VERSION "HNPBNNNYNNNNNNNNNNNNNNNNNNNNNNNNYNYYYYYYYY>4>%%%/4>'%**4YYY///"

NS_ :

BS_:

BU_: HFM IMU AP_HMI SalvatorX CAN2LIN_GW
VAL_TABLE_ Vt_APHMIInGarageParkingState 6 "GP_IN_DETECTED_BWD" 5 "GP_IN_DETECTED_FWD" 4 "GP_OUT_BWD" 3 "GP_OUT_FWD" 2 "GP_IN_SCAN_BWD" 1 "GP_IN_SCAN_FWD" 0 "GP_NOT_AVAIABLE" ;
VAL_TABLE_ DrivingTubeDirection 1 "LEFT" 0 "RIGHT" ;
VAL_TABLE_ DrivingTubeDisplay 3 "BOTH" 2 "REAR" 1 "FRONT" 0 "NONE" ;
VAL_TABLE_ TubeRadius 65535 "UNKNOWN" 65534 "INFINITE" ;
VAL_TABLE_ SV_SCREEN_REQUESTS 255 "NO_STREAM_CHANGE" 222 "DEBUG_RAW_CAMERAS_SFM" 221 "DEBUG_RAW_CAMERAS" 220 "DEBUG_COLOUR_BARS" 219 "DEBUG_CALIBRATION_OLMC_QUAD_VIEW" 218 "DEBUG_TESTSCREEN_4_CAMS" 217 "DEBUG_CALIBRATION_PGM_QUAD_VIEW" 216 "DEBUG_CALIBRATION_FLMC_QUAD_VIEW" 215 "DEBUG_RIGHT_CAMERA_CLEANING" 214 "DEBUG_RIGHT_CAMERA_EDGES" 213 "DEBUG_RIGHT_CAMERA_VECTORS" 212 "DEBUG_RIGHT_CAMERA_EXTERN" 211 "DEBUG_LEFT_CAMERA_CLEANING" 210 "DEBUG_LEFT_CAMERA_EDGES" 209 "DEBUG_LEFT_CAMERA_VECTORS" 208 "DEBUG_LEFT_CAMERA_EXTERN" 207 "DEBUG_REAR_CAMERA_CLEANING" 206 "DEBUG_REAR_CAMERA_EDGES" 205 "DEBUG_REAR_CAMERA_VECTORS" 204 "DEBUG_REAR_CAMERA_EXTERN" 203 "DEBUG_FRONT_CAMERA_CLEANING" 202 "DEBUG_FRONT_CAMERA_EDGES" 201 "DEBUG_FRONT_CAMERA_VECTORS" 200 "DEBUG_FRONT_CAMERA_EXTERN" 151 "SMARTPHONE_VIEW" 93 "IPA_TOP_VIEW" 92 "IPA_REAR_VIEW" 91 "IPA_FRONT_VIEW" 79 "ARA_PANORAMIC_IRREGULAR" 78 "ARA_PANORAMIC_NORMAL" 77 "ARA_REAR_IRREGULAR" 76 "ARA_REAR_NORMAL" 62 "KERB_VIEW_REAR" 61 "KERB_VIEW_FRONT" 49 "TRAILER_VIEW" 48 "PANORAMIC_REAR_VIEW" 47 "REAR_VIEW_SPLIT" 46 "REAR_VIEW_FULL" 34 "TOP_VIEW_PMD" 33 "TOP_VIEW_PSD" 32 "TOP_VIEW_SFM" 31 "TOP_VIEW" 18 "PANORAMIC_FRONT_VIEW" 17 "FRONT_VIEW_SPLIT" 16 "FRONT_VIEW_FULL" 15 "BOWL_VIEW_MODIFIED" 14 "BOWL_VIEW_14" 13 "BOWL_VIEW_13" 12 "BOWL_VIEW_12" 11 "BOWL_VIEW_11" 10 "BOWL_VIEW_10" 9 "BOWL_VIEW_9" 8 "BOWL_VIEW_8" 7 "BOWL_VIEW_7" 6 "BOWL_VIEW_6" 5 "BOWL_VIEW_5" 4 "BOWL_VIEW_4" 3 "BOWL_VIEW_3" 2 "BOWL_VIEW_2" 1 "BOWL_VIEW_1" 0 "BLANK_SCREEN" ;
VAL_TABLE_ Gesture_Code 31 "INVALID" 30 "NO_ACTION" 11 "FLICK" 10 "TRIPLE_CLICK" 9 "DOUBLE_CLICK" 8 "RAW" 7 "ROTATE" 6 "ZOOM" 5 "DRAG" 4 "RIGHT_CLICK" 3 "CLICK" 2 "RELEASE" 1 "LONG_PRESS" 0 "PRESS" ;
VAL_TABLE_ VSig_maxSpeed10Warning 2 "BLINKING" 1 "CONTINUOUS" 0 "OFF" ;
VAL_TABLE_ Vt_Lean_angle_signal_status 15 "Reserved" 14 "Reserved" 13 "Reserved" 12 "Reserved" 11 "Reserved" 10 "Reserved" 9 "Reserved" 8 "Reserved" 7 "Reserved" 6 "Reserved" 5 "Reserved" 4 "Reserved" 3 "Initialization running" 2 "Signal fault" 1 "Sensor not available" 0 "No error" ;
VAL_TABLE_ Vt_Sensor_status 15 "Not defined" 14 "Not defined" 13 "Not defined" 12 "Not defined" 11 "Not defined" 10 "Not defined" 9 "Not defined" 8 "Synchronization failure" 7 "Not defined" 6 "Not defined" 5 "Not defined" 4 "Synchronization underflow" 3 "Not defined" 2 "Overvoltage detected" 1 "Undervoltage detected" 0 "No error" ;
VAL_TABLE_ CECC_MODES 2 "CECC_ERROR" 1 "CECC_CONTROLLING" 0 "CECC_OFF" ;
VAL_TABLE_ CECC_LIMITING_FCNS 5 "CECC_CLOUD" 4 "CECC_FOLLOW" 3 "CECC_SPEED_LIMIT" 2 "CECC_CURVE" 1 "CECC_DRIVER" 0 "CECC_OFF" ;
VAL_TABLE_ VehicleId 12 "LI-DC507" 11 "F-TZ330" 10 "R-CO220" 9 "F-TZ5000" 8 "F-TZ990" 7 "PassatJapan" 6 "F-TZ880" 5 "F-TZ660" 4 "F-TZ440" 3 "GG-ZV542" 2 "F-TZ560" 1 "F-TZ2222" 0 "Fzg. unbekannt" ;
VAL_TABLE_ VTSig_Mode_Gaspedalkennlinie 2 "Vorgabe einer Gaspedalstellung" 1 "Modifiziert anhand Stützstellen" 0 "Originalkennlinie" ;
VAL_TABLE_ parkReq 3 "hold permanently" 2 "hold temporarily" 1 "release" 0 "stay" ;
VAL_TABLE_ gearReq 3 "forward" 2 "neutral" 1 "backward" 0 "stay" ;
VAL_TABLE_ GlblTm_Multiplex 2 "gpsTime" 1 "sysTimestamp" 0 "msgCount" ;
VAL_TABLE_ RCG_LED 1 "ein" 0 "aus" ;
VAL_TABLE_ SwitchACCOff 1 "yes" 0 "no" ;
VAL_TABLE_ SwitchACCOn 1 "yes" 0 "no" ;
VAL_TABLE_ InterventionTypeCenter 15 "LCA" 14 "no intervention" 13 "LCA" 12 "no intervention" 11 "LCA" 10 "no intervention" 9 "LCA" 8 "no intervention" 7 "LCA" 6 "no intervention" 5 "LCA" 4 "no intervention" 3 "LCA" 2 "no intervention" 1 "LCA" 0 "no intervention" ;
VAL_TABLE_ InterventionTypeLeftRight 15 "VWall & LDW" 14 "LDW" 13 "VWall" 12 "no intervention" 11 "VWall & LDW" 10 "LDW" 9 "VWall" 8 "no intervention" 7 "VWall & LDW" 6 "LDW" 5 "VWall" 4 "no intervention" 3 "VWall & LDW" 2 "LDW" 1 "VWall" 0 "no intervention" ;
VAL_TABLE_ VLongRequestType 1 "NORMAL_V_REQUEST" 0 "OFF" ;
VAL_TABLE_ ALongRequestType 2 "NORMAL_A_REQUEST" 1 "RAMP_DOWN_MODE" 0 "OFF" ;
VAL_TABLE_ AFFPJitterFrequency 3 "40Hz" 2 "30Hz" 1 "20Hz" 0 "10Hz" ;
VAL_TABLE_ AFFPJitterForm 3 "undef." 2 "Rectangle" 1 "Sawtooth" 0 "Sinus" ;
VAL_TABLE_ AFFPJitterAmplitude 7 "70% of AFFPForce" 6 "60% of AFFPForce" 5 "50% of AFFPForce" 4 "40% of AFFPForce" 3 "30% of AFFPForce" 2 "20% of AFFPForce" 1 "10% of AFFPForce" 0 "0% of AFFPForce" ;
VAL_TABLE_ AGB_IMU_True_False 1 "True" 0 "False" ;
VAL_TABLE_ AGB_IMU_InValid_Valid 1 "Invalid" 0 "Valid" ;
VAL_TABLE_ LateralMarginType 2 "Vehicle" 1 "CrashBarrier" 0 "Line" ;
VAL_TABLE_ VtAvidLed 1 "LED switched on" 0 "LED off" ;
VAL_TABLE_ VtAGB_ReqMaxEngTqStatus 1 "No AGB request active" 0 "AGB requests torque reduction" ;
VAL_TABLE_ LaLdwActiveState 7 "LDW Suppressed Right + Left" 6 "- *" 5 "LDW Suppressed Right" 4 "LDW Warning Right" 3 "LDW Suppressed Left" 2 "LDW Warning Left" 1 "- *" 0 "LDW Idle *" ;
VAL_TABLE_ LaLkaLcaActiveState 7 "LKA/LCA Suppressed Right + Left" 6 "LCA in Progress * (Intervention Right + Left so to say)" 5 "LKA Suppressed Right" 4 "LKA Intervention Right" 3 "LKA Suppressed Left" 2 "LKA Intervention Left" 1 "LKA Idle, LCA Suppressed *" 0 "LKA Idle *" ;
VAL_TABLE_ Vt_BOOL 0 "FALSE" 1 "TRUE" ;
VAL_TABLE_ Vt_APHMIGeneralScreen 0 "SYSTEM_NOT_ACTIVE" 1 "SCANNING_ACTIVE" 2 "PARKING_SPACE_SELECTION" 3 "REMOTE_APP_ACTIVE" 4 "MANEUVER_ACTIVE" 5 "MANEUVER_FINISHED" 6 "MANEUVER_INTERRUPTED" 7 "UNDO_MANEUVER_ACTIVE" 8 "START_REMOTE_APP" 9 "PARK_OUT_INIT" 10 "PARK_OUT_SIDE" 11 "MENU_REM" 12 "MANEUVER_ACTIVE_LONG_MAN" 13 "REM_SV" 14 "REM_MAN" 15 "REM_MAN_ACTIVE" ;
VAL_TABLE_ Vt_APHMIGeneralMessage 39 "PARKING_OUT_FINISHED_FALLBACK" 38 "PARKING_IN_FINISHED_FALLBACK" 37 "KEY_NOT_ALIVE" 36 "KEY_NOT_IN_RANGE" 35 "SLOW_DOWN" 34 "WAIT" 33 "LOW_ENERGY" 32 "UNDO_FINISHED" 31 "GARAGE_NOT_OPEN" 30 "PARKING_CANCELLED_STEER" 29 "PARKING_CANCELLED_THROTTLE" 28 "NO_REMOTE_DEVICE_CONNECTED" 27 "NO_REMOTE_DEVICE_PAIRED" 26 "SELECT_PARKING_VARIANT" 25 "SHIFT_TO_N" 24 "SHIFT_TO_P" 0 "NO_MESSAGE" 1 "VERY_CLOSE_TO_OBJECTS" 2 "START_PARKING_IN" 3 "PARKING_IN_FINISHED" 4 "PARKING_CANCELLED" 5 "PARKING_FAILED" 6 "SHIFT_TO_R" 7 "SHIFT_TO_D" 8 "SHIFT_TO_1" 9 "RELEASE_BRAKE" 10 "START_PARKING_OUT" 11 "PARKING_OUT_FINISHED" 12 "START_REM_MAN" 13 "REM_MAN_OBSTACLE_STOP" 14 "REDUCE_DISTANCE_TO_VEHICLE" 15 "CLOSE_DOOR_OR_START_REMOTE" 16 "RELEASE_HANDBRAKE" 17 "LEAVE_VEHICLE" 18 "NO_DRIVER_DETECTED_ON_SEAT" 19 "INTERNAL_SYSTEM_ERROR" 20 "PARKING_OUT_HANDOVER" 21 "STEERING_ACTIVE" 22 "STOP" 23 "MAX_WAITING_TIME_EXCEEDED" ;
VAL_TABLE_ Vt_APHMIGeneralDrivingDir 0 "NO_DIRECTION" 1 "FORWARDS" 2 "BACKWARDS" ;
VAL_TABLE_ Vt_APHMIGeneralAVGType 0 "NO_AVG_TYPE" 1 "PARK_IN_PARALLEL_LEFT" 2 "PARK_IN_PARALLEL_RIGHT" 3 "PARK_IN_PERPENDICULAR_LEFT_FWD" 4 "PARK_IN_PERPENDICULAR_LEFT_BWD" 5 "PARK_IN_PERPENDICULAR_RIGHT_FWD" 6 "PARK_IN_PERPENDICULAR_RIGHT_BWD" 7 "PARK_OUT_PARALLEL_LEFT" 8 "PARK_OUT_PARALLEL_RIGHT" 9 "PARK_OUT_PERPENDICULAR_LEFT_FWD" 10 "PARK_OUT_PERPENDICULAR_LEFT_BWD" 11 "PARK_OUT_PERPENDICULAR_RIGHT_FWD" 12 "PARK_OUT_PERPENDICULAR_RIGHT_BWD" 13 "REM_MAN_FWD" 14 "REM_MAN_BWD" ;
VAL_TABLE_ Vt_APHMICurrentGear 0 "N" 1 "1" 2 "2" 3 "3" 4 "4" 5 "5" 6 "6" 7 "7" 8 "8" 9 "9" 10 "INTERMEDIATE_POS" 11 "R" 12 "P" 13 "S" 14 "GEAR_NOT_DEFINED" 15 "ERROR" ;
VAL_TABLE_ Vt_APHMIParkStatProcCtrlState 0 "PPC_INACTIVE" 1 "PPC_BEHAVIOR_INACTIVE" 2 "PPC_SCANNING_INACTIVE" 3 "PPC_SCANNING_IN" 4 "PPC_SCANNING_OUT" 5 "PPC_SCANNING_RM" 6 "PPC_PARKING_INACTIVE" 7 "PPC_PREPARE_PARKING" 8 "PPC_PERFORM_PARKING" 9 "PPC_PARKING_PAUSE" 10 "PPC_PARKING_FAILED" 11 "PPC_OFFER_HANDOVER" 12 "PPC_SUCCESS" 13 "PPC_PARKING_CANCELED" 14 "PPC_IRREVERSIBLE_ERROR" 15 "PPC_REVERSIBLE_ERROR" 23 "PPC_DEMO_OFF" ;
VAL_TABLE_ Vt_APHMIParkSlotPossOrient 0 "CERTAIN" 1 "UNCERTAIN" ;
VAL_TABLE_ Vt_APHMIParkSlotSelOrient 0 "PARALLEL" 1 "PERPENDICULAR" ;
VAL_TABLE_ Vt_APHMIParkSlotPossDir 0 "ONE_DIRECTION" 1 "BOTH_DIRECTIONS" ;
VAL_TABLE_ Vt_APHMIParkSlotSelDir 0 "FORWARDS" 1 "BACKWARDS" ;
VAL_TABLE_ Vt_APHMIParkDistViewLow 0 "L_NOT_OCCUPIED" 1 "L_OUTERMOST_BAR_OCCUPIED" 2 "L_BAR_2_OCCUPIED" 3 "L_INNERMOST_BAR_OCCUPIED" ;
VAL_TABLE_ Vt_APHMIParkDistViewHigh 0 "H_NOT_OCCUPIED" 1 "H_OUTERMOST_BAR_OCCUPIED" 2 "H_BAR_2_OCCUPIED" 3 "H_BAR_3_OCCUPIED" 4 "H_BAR_4_OCCUPIED" 5 "H_BAR_5_OCCUPIED" 6 "H_BAR_6_OCCUPIED" 7 "H_INNERMOST_BAR_OCCUPIED" ;
VAL_TABLE_ Vt_APHMIScreenDisplayed 0 "SYSTEM_NOT_ACTIVE" 1 "SCANNING_ACTIVE" 2 "PARKING_SPACE_SELECTION" 3 "REMOTE_APP_ACTIVE" 4 "MANEUVER_ACTIVE" 5 "MANEUVER_FINISHED" 6 "MANEUVER_INTERRUPTED" 7 "UNDO_MANEUVER_ACTIVE" 8 "START_REMOTE_APP" 9 "PARK_OUT_INIT" 10 "PARK_OUT_SIDE" 11 "MENU_REM" 12 "MANEUVER_ACTIVE_LONG_MAN" 13 "REM_SV" 14 "REM_MAN" 15 "REM_MAN_ACTIVE" ;
VAL_TABLE_ Vt_APHMIPushedButton 0 "NO_USER_ACTION" 1 "TAP_ON_PARKING_SPACE_LEFT_1" 2 "TAP_ON_PARKING_SPACE_LEFT_2" 3 "TAP_ON_PARKING_SPACE_LEFT_3" 4 "TAP_ON_PARKING_SPACE_LEFT_4" 5 "TAP_ON_PARKING_SPACE_RIGHT_1" 6 "TAP_ON_PARKING_SPACE_RIGHT_2" 7 "TAP_ON_PARKING_SPACE_RIGHT_3" 8 "TAP_ON_PARKING_SPACE_RIGHT_4" 9 "TAP_ON_PARKING_SPACE_FRONT_1" 10 "TAP_ON_PARKING_SPACE_FRONT_2" 11 "TAP_ON_PARKING_SPACE_FRONT_3" 12 "TAP_ON_PARKING_SPACE_FRONT_4" 13 "TAP_ON_PARKING_SPACE_REAR_1" 14 "TAP_ON_PARKING_SPACE_REAR_2" 15 "TAP_ON_PARKING_SPACE_REAR_3" 16 "TAP_ON_PARKING_SPACE_REAR_4" 17 "TAP_ON_START_SELECTION" 18 "TAP_ON_START_PARKING" 19 "TAP_ON_INTERRUPT" 20 "TAP_ON_CONTINUE" 21 "TAP_ON_UNDO" 22 "TAP_ON_CANCEL" 23 "TAP_ON_REDO" 24 "TAP_ON_START_REMOTE_PARKING" 25 "TAP_ON_SWITCH_DIRECTION" 26 "TAP_ON_SWITCH_ORIENTATION" 27 "TAP_ON_PREVIOUS_SCREEN" 28 "TOGGLE_AP_ACTIVE" ;
VAL_TABLE_ Vt_ParkSituation 0 "NO_SITUATION" 1 "PERPENDICULAR" 2 "PARALLEL" 3 "ANGLED" 4 "STREET" 5 "UNCERTAIN" 6 "PARALLEL_OUT" 7 "NOT_AVAILABLE" 15 "SNA" ;
VAL_TABLE_ Vt_PushedButton 0 "NO_USER_ACTION" 1 "TAP_ON_PARKING_SPACE_LEFT_1" 2 "TAP_ON_PARKING_SPACE_LEFT_2" 3 "TAP_ON_PARKING_SPACE_LEFT_3" 4 "TAP_ON_PARKING_SPACE_LEFT_4" 5 "TAP_ON_PARKING_SPACE_RIGHT_1" 6 "TAP_ON_PARKING_SPACE_RIGHT_2" 7 "TAP_ON_PARKING_SPACE_RIGHT_3" 8 "TAP_ON_PARKING_SPACE_RIGHT_4" 9 "TAP_ON_PARKING_SPACE_FRONT_1" 10 "TAP_ON_PARKING_SPACE_FRONT_2" 11 "TAP_ON_PARKING_SPACE_FRONT_3" 12 "TAP_ON_PARKING_SPACE_FRONT_4" 13 "TAP_ON_PARKING_SPACE_REAR_1" 14 "TAP_ON_PARKING_SPACE_REAR_2" 15 "TAP_ON_PARKING_SPACE_REAR_3" 16 "TAP_ON_PARKING_SPACE_REAR_4" 17 "TAP_ON_START_SELECTION" 18 "TAP_ON_START_PARKING" 19 "TAP_ON_INTERRUPT" 20 "TAP_ON_CONTINUE" 21 "TAP_ON_UNDO" 22 "TAP_ON_CANCEL" 23 "TAP_ON_REDO" 24 "TAP_ON_START_REMOTE_PARKING" 25 "TAP_ON_SWITCH_DIRECTION" 26 "TAP_ON_SWITCH_ORIENTATION" 27 "TAP_ON_PREVIOUS_SCREEN" 28 "TOGGLE_AP_ACTIVE" ;

BO_ 3221225472 VECTOR__INDEPENDENT_SIG_MSG: 0 Vector__XXX
 SG_ APHMIGeneralReserved : 0|1@1+ (1,0) [0|0] "" Vector__XXX

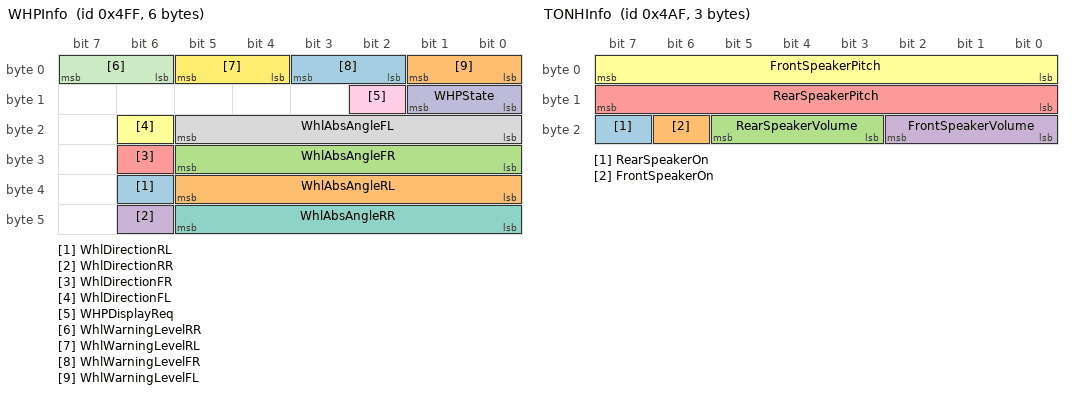
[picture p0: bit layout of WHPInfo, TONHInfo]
BO_ 1279 WHPInfo: 6 SalvatorX
 SG_ WhlDirectionRL : 38|1@1+ (1,0) [0|0] ""  AP_HMI
 SG_ WhlAbsAngleRL : 32|6@1+ (1,0) [0|0] "deg"  AP_HMI
 SG_ WhlAbsAngleFR : 24|6@1+ (1,0) [0|0] "deg"  AP_HMI
 SG_ WhlDirectionRR : 46|1@1+ (1,0) [0|0] ""  AP_HMI
 SG_ WhlDirectionFR : 30|1@1+ (1,0) [0|0] ""  AP_HMI
 SG_ WhlDirectionFL : 22|1@1+ (1,0) [0|0] ""  AP_HMI
 SG_ WhlAbsAngleRR : 40|6@1+ (1,0) [0|0] "deg"  AP_HMI
 SG_ WhlAbsAngleFL : 16|6@1+ (1,0) [0|0] "deg"  AP_HMI
 SG_ WHPDisplayReq : 10|1@1+ (1,0) [0|1] ""  AP_HMI
 SG_ WHPState : 8|2@1+ (1,0) [0|3] ""  AP_HMI
 SG_ WhlWarningLevelRR : 6|2@1+ (1,0) [0|3] ""  AP_HMI
 SG_ WhlWarningLevelRL : 4|2@1+ (1,0) [0|3] ""  AP_HMI
 SG_ WhlWarningLevelFR : 2|2@1+ (1,0) [0|3] ""  AP_HMI
 SG_ WhlWarningLevelFL : 0|2@1+ (1,0) [0|3] ""  AP_HMI

BO_ 1199 TONHInfo: 3 SalvatorX
 SG_ RearSpeakerOn : 23|1@1+ (1,0) [0|1] ""  AP_HMI
 SG_ FrontSpeakerOn : 22|1@1+ (1,0) [0|1] ""  AP_HMI
 SG_ RearSpeakerVolume : 19|3@1+ (1,0) [0|7] ""  AP_HMI
 SG_ FrontSpeakerVolume : 16|3@1+ (1,0) [0|7] ""  AP_HMI
 SG_ RearSpeakerPitch : 8|8@1+ (1,0) [0|255] ""  AP_HMI
 SG_ FrontSpeakerPitch : 0|8@1+ (1,0) [0|255] ""  AP_HMI

BO_ 1198 APHMIOut4: 8 AP_HMI
 SG_ APHMIOutRemScreenResY : 14|14@1+ (1,0) [0|16384] "px"  SalvatorX
 SG_ APHMIOutRemScreenResX : 0|14@1+ (1,0) [0|16384] "px"  SalvatorX

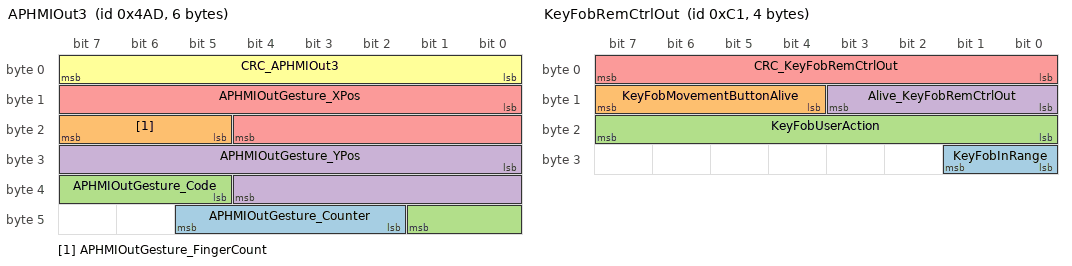
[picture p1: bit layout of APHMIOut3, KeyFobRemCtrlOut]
BO_ 1197 APHMIOut3: 6 AP_HMI
 SG_ APHMIOutGesture_Counter : 42|4@1+ (1,0) [0|15] ""  SalvatorX
 SG_ APHMIOutGesture_FingerCount : 21|3@1+ (1,0) [0|0] ""  SalvatorX
 SG_ APHMIOutGesture_Code : 37|5@1+ (1,0) [0|0] ""  SalvatorX
 SG_ APHMIOutGesture_YPos : 24|13@1+ (1,0) [0|0] ""  SalvatorX
 SG_ APHMIOutGesture_XPos : 8|13@1+ (1,0) [0|0] ""  SalvatorX
 SG_ CRC_APHMIOut3 : 0|8@1+ (1,0) [0|0] ""  SalvatorX

BO_ 193 KeyFobRemCtrlOut: 4 HFM
 SG_ KeyFobInRange : 24|2@1+ (1,0) [0|3] ""  SalvatorX
 SG_ KeyFobMovementButtonAlive : 12|4@1+ (1,0) [0|15] ""  SalvatorX
 SG_ KeyFobUserAction : 16|8@1+ (1,0) [0|255] ""  SalvatorX
 SG_ Alive_KeyFobRemCtrlOut : 8|4@1+ (1,0) [0|15] ""  SalvatorX
 SG_ CRC_KeyFobRemCtrlOut : 0|8@1+ (1,0) [0|255] ""  SalvatorX

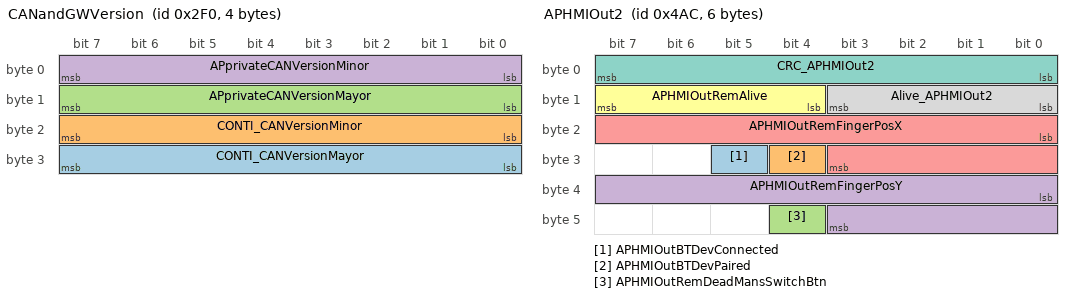
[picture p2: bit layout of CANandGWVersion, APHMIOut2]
BO_ 752 CANandGWVersion: 4 SalvatorX
 SG_ CONTI_CANVersionMayor : 24|8@1+ (1,0) [0|255] ""  AP_HMI
 SG_ CONTI_CANVersionMinor : 16|8@1+ (1,0) [0|255] ""  AP_HMI
 SG_ APprivateCANVersionMayor : 8|8@1+ (1,0) [0|255] ""  AP_HMI
 SG_ APprivateCANVersionMinor : 0|8@1+ (1,0) [0|255] ""  AP_HMI

BO_ 1196 APHMIOut2: 6 AP_HMI
 SG_ APHMIOutBTDevConnected : 29|1@1+ (1,0) [0|1] ""  SalvatorX
 SG_ APHMIOutBTDevPaired : 28|1@1+ (1,0) [0|1] ""  SalvatorX
 SG_ APHMIOutRemDeadMansSwitchBtn : 44|1@1+ (1,0) [0|1] ""  SalvatorX
 SG_ APHMIOutRemFingerPosY : 32|12@1+ (1,0) [0|4095] "px"  SalvatorX
 SG_ APHMIOutRemFingerPosX : 16|12@1+ (1,0) [0|4095] "px"  SalvatorX
 SG_ APHMIOutRemAlive : 12|4@1+ (1,0) [0|15] ""  SalvatorX
 SG_ CRC_APHMIOut2 : 0|8@1+ (1,0) [0|255] ""  SalvatorX
 SG_ Alive_APHMIOut2 : 8|4@1+ (1,0) [0|15] ""  SalvatorX

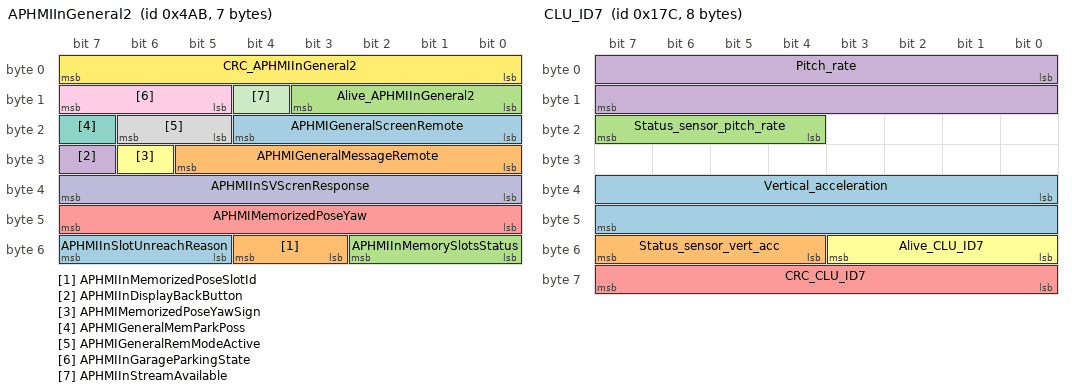
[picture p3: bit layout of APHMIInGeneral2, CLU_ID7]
BO_ 1195 APHMIInGeneral2: 7 SalvatorX
 SG_ APHMIInSlotUnreachReason : 53|3@1+ (1,0) [0|7] ""  AP_HMI
 SG_ APHMIInMemorizedPoseSlotId : 51|2@1+ (1,0) [0|3] ""  AP_HMI
 SG_ APHMIInMemorySlotsStatus : 48|3@1+ (1,0) [0|7] ""  AP_HMI
 SG_ APHMIInDisplayBackButton : 31|1@1+ (1,0) [0|1] ""  AP_HMI
 SG_ APHMIMemorizedPoseYaw : 40|8@1+ (1,0) [0|180] "deg"  AP_HMI
 SG_ APHMIMemorizedPoseYawSign : 30|1@1+ (1,0) [0|1] ""  AP_HMI
 SG_ APHMIGeneralMemParkPoss : 23|1@1+ (1,0) [0|1] ""  AP_HMI
 SG_ APHMIGeneralRemModeActive : 21|2@1+ (1,0) [0|3] ""  AP_HMI
 SG_ APHMIInGarageParkingState : 13|3@1+ (1,0) [0|0] ""  AP_HMI
 SG_ APHMIInSVScrenResponse : 32|8@1+ (1,0) [0|0] ""  AP_HMI
 SG_ APHMIInStreamAvailable : 12|1@1+ (1,0) [0|0] ""  AP_HMI
 SG_ CRC_APHMIInGeneral2 : 0|8@1+ (1,0) [0|255] ""  AP_HMI
 SG_ APHMIGeneralScreenRemote : 16|5@1+ (1,0) [0|0] ""  AP_HMI
 SG_ APHMIGeneralMessageRemote : 24|6@1+ (1,0) [0|0] ""  AP_HMI
 SG_ Alive_APHMIInGeneral2 : 8|4@1+ (1,0) [0|15] ""  AP_HMI

BO_ 380 CLU_ID7: 8 IMU
 SG_ Vertical_acceleration : 32|16@1+ (0.0002,-6.55) [-6.55|6.55] "g"  SalvatorX
 SG_ Status_sensor_vert_acc : 52|4@1+ (1,0) [0|15] ""  SalvatorX
 SG_ Status_sensor_pitch_rate : 20|4@1+ (1,0) [0|15] ""  SalvatorX
 SG_ Pitch_rate : 0|16@1+ (0.01,-327.68) [-327.68|327.67] "deg/s"  SalvatorX
 SG_ CRC_CLU_ID7 : 56|8@1+ (1,0) [0|255] ""  SalvatorX
 SG_ Alive_CLU_ID7 : 48|4@1+ (1,0) [0|15] ""  SalvatorX

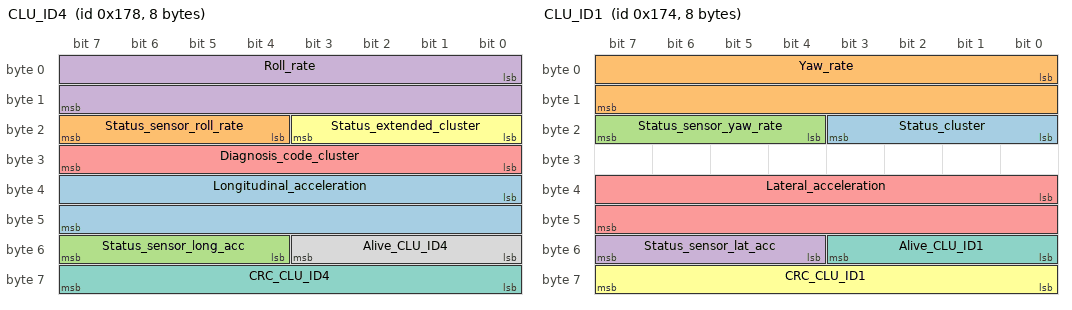
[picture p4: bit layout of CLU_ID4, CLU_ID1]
BO_ 376 CLU_ID4: 8 IMU
 SG_ Longitudinal_acceleration : 32|16@1+ (-0.0002,6.55) [-6.557|6.55] "g"  SalvatorX
 SG_ Status_sensor_roll_rate : 20|4@1+ (1,0) [0|15] ""  SalvatorX
 SG_ Status_sensor_long_acc : 52|4@1+ (1,0) [0|15] ""  SalvatorX
 SG_ Roll_rate : 0|16@1+ (-0.01,327.68) [-327.67|327.68] "deg/s"  SalvatorX
 SG_ Diagnosis_code_cluster : 24|8@1+ (1,0) [0|0] ""  SalvatorX
 SG_ Status_extended_cluster : 16|4@1+ (1,0) [0|15] ""  SalvatorX
 SG_ CRC_CLU_ID4 : 56|8@1+ (1,0) [0|255] ""  SalvatorX
 SG_ Alive_CLU_ID4 : 48|4@1+ (1,0) [0|15] ""  SalvatorX

BO_ 372 CLU_ID1: 8 IMU
 SG_ Status_cluster : 16|4@1+ (1,0) [0|15] ""  SalvatorX
 SG_ Yaw_rate : 0|16@1+ (-0.01,327.68) [-327.67|327.68] "deg/s"  SalvatorX
 SG_ Status_sensor_yaw_rate : 20|4@1+ (1,0) [0|15] ""  SalvatorX
 SG_ Status_sensor_lat_acc : 52|4@1+ (1,0) [0|15] ""  SalvatorX
 SG_ Lateral_acceleration : 32|16@1+ (-0.0002,6.55) [-6.557|6.55] "g"  SalvatorX
 SG_ CRC_CLU_ID1 : 56|8@1+ (1,0) [0|255] ""  SalvatorX
 SG_ Alive_CLU_ID1 : 48|4@1+ (1,0) [0|15] ""  SalvatorX

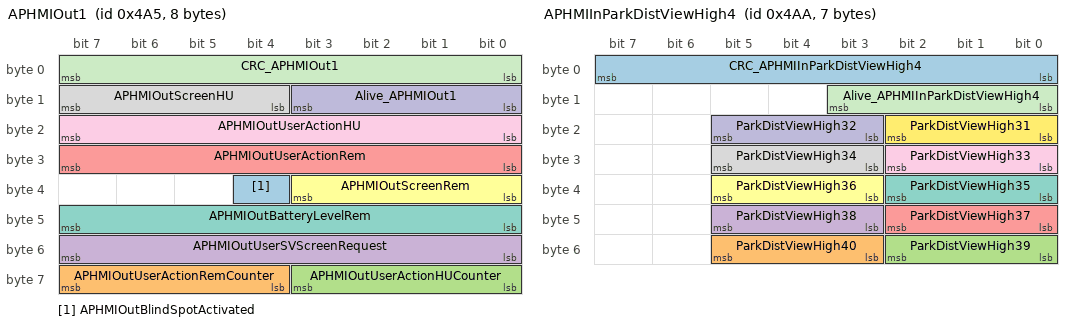
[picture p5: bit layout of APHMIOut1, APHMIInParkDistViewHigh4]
BO_ 1189 APHMIOut1: 8 AP_HMI
 SG_ APHMIOutBlindSpotActivated : 36|1@1+ (1,0) [0|1] ""  SalvatorX
 SG_ APHMIOutUserActionRemCounter : 60|4@1+ (1,0) [0|15] ""  SalvatorX
 SG_ APHMIOutUserActionHUCounter : 56|4@1+ (1,0) [0|15] ""  SalvatorX
 SG_ APHMIOutUserSVScreenRequest : 48|8@1+ (1,0) [0|0] ""  SalvatorX
 SG_ APHMIOutUserActionRem : 24|8@1+ (1,0) [0|255] ""  SalvatorX
 SG_ APHMIOutScreenRem : 32|4@1+ (1,0) [0|15] ""  SalvatorX
 SG_ APHMIOutBatteryLevelRem : 40|8@1+ (0.4,0) [0|102] "%"  SalvatorX
 SG_ APHMIOutScreenHU : 12|4@1+ (1,0) [0|15] ""  SalvatorX
 SG_ APHMIOutUserActionHU : 16|8@1+ (1,0) [0|255] ""  SalvatorX
 SG_ Alive_APHMIOut1 : 8|4@1+ (1,0) [0|15] ""  SalvatorX
 SG_ CRC_APHMIOut1 : 0|8@1+ (1,0) [0|255] ""  SalvatorX

BO_ 1194 APHMIInParkDistViewHigh4: 7 SalvatorX
 SG_ CRC_APHMIInParkDistViewHigh4 : 0|8@1+ (1,0) [0|255] ""  AP_HMI
 SG_ ParkDistViewHigh40 : 51|3@1+ (1,0) [0|7] ""  AP_HMI
 SG_ ParkDistViewHigh39 : 48|3@1+ (1,0) [0|7] ""  AP_HMI
 SG_ ParkDistViewHigh38 : 43|3@1+ (1,0) [0|7] ""  AP_HMI
 SG_ ParkDistViewHigh37 : 40|3@1+ (1,0) [0|7] ""  AP_HMI
 SG_ ParkDistViewHigh36 : 35|3@1+ (1,0) [0|7] ""  AP_HMI
 SG_ ParkDistViewHigh35 : 32|3@1+ (1,0) [0|7] ""  AP_HMI
 SG_ ParkDistViewHigh34 : 27|3@1+ (1,0) [0|7] ""  AP_HMI
 SG_ ParkDistViewHigh33 : 24|3@1+ (1,0) [0|7] ""  AP_HMI
 SG_ ParkDistViewHigh32 : 19|3@1+ (1,0) [0|7] ""  AP_HMI
 SG_ Alive_APHMIInParkDistViewHigh4 : 8|4@1+ (1,0) [0|15] ""  AP_HMI
 SG_ ParkDistViewHigh31 : 16|3@1+ (1,0) [0|7] ""  AP_HMI

BO_ 1193 PDCRearAndRight: 8 SalvatorX
 SG_ PDCRear1IntersectDrvTube : 6|1@1+ (1,0) [0|3] ""  AP_HMI
 SG_ PDCRear1Slice : 3|3@1+ (1,0) [0|3] ""  AP_HMI
 SG_ PDCRear1CriticalLevel : 0|3@1+ (1,0) [0|3] ""  AP_HMI
 SG_ PDCRear2IntersectDrvTube : 14|1@1+ (1,0) [0|3] ""  AP_HMI
 SG_ PDCRear2Slice : 11|3@1+ (1,0) [0|3] ""  AP_HMI
 SG_ PDCRear2CriticalLevel : 8|3@1+ (1,0) [0|3] ""  AP_HMI
 SG_ PDCRear3IntersectDrvTube : 22|1@1+ (1,0) [0|3] ""  AP_HMI
 SG_ PDCRear3Slice : 19|3@1+ (1,0) [0|3] ""  AP_HMI
 SG_ PDCRear3CriticalLevel : 16|3@1+ (1,0) [0|3] ""  AP_HMI
 SG_ PDCRear4IntersectDrvTube : 30|1@1+ (1,0) [0|3] ""  AP_HMI
 SG_ PDCRear4Slice : 27|3@1+ (1,0) [0|3] ""  AP_HMI
 SG_ PDCRear4CriticalLevel : 24|3@1+ (1,0) [0|3] ""  AP_HMI
 SG_ PDCRight1IntersectDrvTube : 38|1@1+ (1,0) [0|3] ""  AP_HMI
 SG_ PDCRight1Slice : 35|3@1+ (1,0) [0|3] ""  AP_HMI
 SG_ PDCRight1CriticalLevel : 32|3@1+ (1,0) [0|3] ""  AP_HMI
 SG_ PDCRight2IntersectDrvTube : 46|1@1+ (1,0) [0|3] ""  AP_HMI
 SG_ PDCRight2Slice : 43|3@1+ (1,0) [0|3] ""  AP_HMI
 SG_ PDCRight2CriticalLevel : 40|3@1+ (1,0) [0|3] ""  AP_HMI
 SG_ PDCRight3IntersectDrvTube : 54|1@1+ (1,0) [0|3] ""  AP_HMI
 SG_ PDCRight3Slice : 51|3@1+ (1,0) [0|3] ""  AP_HMI
 SG_ PDCRight3CriticalLevel : 48|3@1+ (1,0) [0|3] ""  AP_HMI
 SG_ PDCRight4IntersectDrvTube : 62|1@1+ (1,0) [0|3] ""  AP_HMI
 SG_ PDCRight4Slice : 59|3@1+ (1,0) [0|3] ""  AP_HMI
 SG_ PDCRight4CriticalLevel : 56|3@1+ (1,0) [0|3] ""  AP_HMI

BO_ 1192 PDCFrontAndLeft: 8 SalvatorX
 SG_ PDCFront1IntersectDrvTube : 6|1@1+ (1,0) [0|3] ""  AP_HMI
 SG_ PDCFront1Slice : 3|3@1+ (1,0) [0|3] ""  AP_HMI
 SG_ PDCFront1CriticalLevel : 0|3@1+ (1,0) [0|3] ""  AP_HMI
 SG_ PDCFront2IntersectDrvTube : 14|1@1+ (1,0) [0|3] ""  AP_HMI
 SG_ PDCFront2Slice : 11|3@1+ (1,0) [0|3] ""  AP_HMI
 SG_ PDCFront2CriticalLevel : 8|3@1+ (1,0) [0|3] ""  AP_HMI
 SG_ PDCFront3IntersectDrvTube : 22|1@1+ (1,0) [0|3] ""  AP_HMI
 SG_ PDCFront3Slice : 19|3@1+ (1,0) [0|3] ""  AP_HMI
 SG_ PDCFront3CriticalLevel : 16|3@1+ (1,0) [0|3] ""  AP_HMI
 SG_ PDCFront4IntersectDrvTube : 30|1@1+ (1,0) [0|3] ""  AP_HMI
 SG_ PDCFront4Slice : 27|3@1+ (1,0) [0|3] ""  AP_HMI
 SG_ PDCFront4CriticalLevel : 24|3@1+ (1,0) [0|3] ""  AP_HMI
 SG_ PDCLeft1IntersectDrvTube : 38|1@1+ (1,0) [0|3] ""  AP_HMI
 SG_ PDCLeft1Slice : 35|3@1+ (1,0) [0|3] ""  AP_HMI
 SG_ PDCLeft1CriticalLevel : 32|3@1+ (1,0) [0|3] ""  AP_HMI
 SG_ PDCLeft2IntersectDrvTube : 46|1@1+ (1,0) [0|3] ""  AP_HMI
 SG_ PDCLeft2Slice : 43|3@1+ (1,0) [0|3] ""  AP_HMI
 SG_ PDCLeft2CriticalLevel : 40|3@1+ (1,0) [0|3] ""  AP_HMI
 SG_ PDCLeft3IntersectDrvTube : 54|1@1+ (1,0) [0|3] ""  AP_HMI
 SG_ PDCLeft3Slice : 51|3@1+ (1,0) [0|3] ""  AP_HMI
 SG_ PDCLeft3CriticalLevel : 48|3@1+ (1,0) [0|3] ""  AP_HMI
 SG_ PDCLeft4IntersectDrvTube : 62|1@1+ (1,0) [0|3] ""  AP_HMI
 SG_ PDCLeft4Slice : 59|3@1+ (1,0) [0|3] ""  AP_HMI
 SG_ PDCLeft4CriticalLevel : 56|3@1+ (1,0) [0|3] ""  AP_HMI

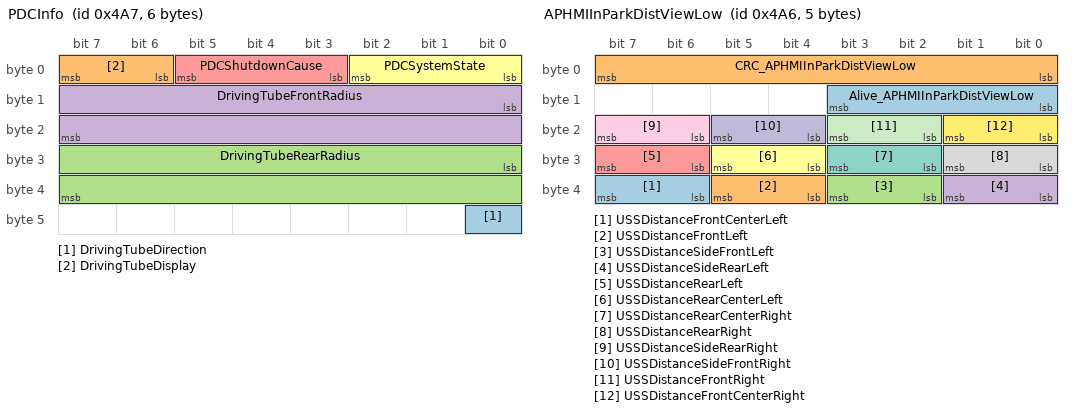
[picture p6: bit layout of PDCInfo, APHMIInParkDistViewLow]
BO_ 1191 PDCInfo: 6 SalvatorX
 SG_ DrivingTubeDirection : 40|1@1+ (1,0) [0|1] ""  AP_HMI
 SG_ DrivingTubeDisplay : 6|2@1+ (1,0) [0|2] ""  AP_HMI
 SG_ DrivingTubeRearRadius : 24|16@1+ (1,0) [0|65535] "cm"  AP_HMI
 SG_ DrivingTubeFrontRadius : 8|16@1+ (1,0) [0|65535] "cm"  AP_HMI
 SG_ PDCShutdownCause : 3|3@1+ (1,0) [0|3] ""  AP_HMI
 SG_ PDCSystemState : 0|3@1+ (1,0) [0|7] ""  AP_HMI

BO_ 1190 APHMIInParkDistViewLow: 5 SalvatorX
 SG_ USSDistanceFrontCenterLeft : 38|2@1+ (1,0) [0|3] ""  AP_HMI
 SG_ USSDistanceFrontLeft : 36|2@1+ (1,0) [0|3] ""  AP_HMI
 SG_ USSDistanceSideFrontLeft : 34|2@1+ (1,0) [0|3] ""  AP_HMI
 SG_ USSDistanceSideRearLeft : 32|2@1+ (1,0) [0|3] ""  AP_HMI
 SG_ USSDistanceRearLeft : 30|2@1+ (1,0) [0|3] ""  AP_HMI
 SG_ USSDistanceRearCenterLeft : 28|2@1+ (1,0) [0|3] ""  AP_HMI
 SG_ USSDistanceRearCenterRight : 26|2@1+ (1,0) [0|3] ""  AP_HMI
 SG_ USSDistanceRearRight : 24|2@1+ (1,0) [0|3] ""  AP_HMI
 SG_ USSDistanceSideRearRight : 22|2@1+ (1,0) [0|3] ""  AP_HMI
 SG_ USSDistanceSideFrontRight : 20|2@1+ (1,0) [0|3] ""  AP_HMI
 SG_ USSDistanceFrontRight : 18|2@1+ (1,0) [0|3] ""  AP_HMI
 SG_ USSDistanceFrontCenterRight : 16|2@1+ (1,0) [0|3] ""  AP_HMI
 SG_ Alive_APHMIInParkDistViewLow : 8|4@1+ (1,0) [0|15] ""  AP_HMI
 SG_ CRC_APHMIInParkDistViewLow : 0|8@1+ (1,0) [0|255] ""  AP_HMI

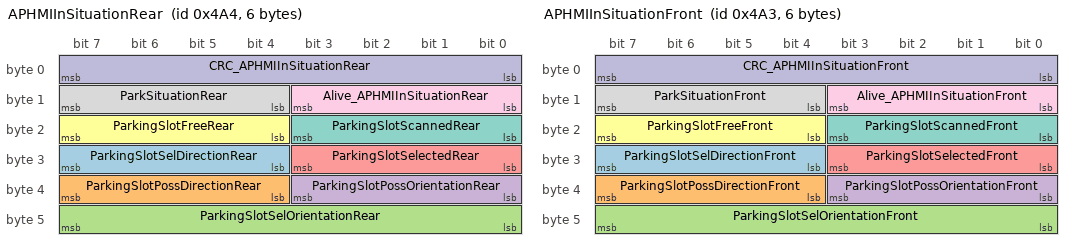
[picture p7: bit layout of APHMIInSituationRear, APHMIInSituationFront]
BO_ 1188 APHMIInSituationRear: 6 SalvatorX
 SG_ ParkingSlotSelDirectionRear : 28|4@1+ (1,0) [0|15] ""  AP_HMI
 SG_ ParkingSlotPossDirectionRear : 36|4@1+ (1,0) [0|15] ""  AP_HMI
 SG_ ParkingSlotSelOrientationRear : 40|8@1+ (1,0) [0|255] ""  AP_HMI
 SG_ ParkingSlotPossOrientationRear : 32|4@1+ (1,0) [0|15] ""  AP_HMI
 SG_ ParkingSlotSelectedRear : 24|4@1+ (1,0) [0|15] ""  AP_HMI
 SG_ ParkingSlotFreeRear : 20|4@1+ (1,0) [0|15] ""  AP_HMI
 SG_ ParkingSlotScannedRear : 16|4@1+ (1,0) [0|15] ""  AP_HMI
 SG_ ParkSituationRear : 12|4@1+ (1,0) [0|15] ""  AP_HMI
 SG_ Alive_APHMIInSituationRear : 8|4@1+ (1,0) [0|15] ""  AP_HMI
 SG_ CRC_APHMIInSituationRear : 0|8@1+ (1,0) [0|255] ""  AP_HMI

BO_ 1187 APHMIInSituationFront: 6 SalvatorX
 SG_ ParkingSlotSelDirectionFront : 28|4@1+ (1,0) [0|15] ""  AP_HMI
 SG_ ParkingSlotPossDirectionFront : 36|4@1+ (1,0) [0|15] ""  AP_HMI
 SG_ ParkingSlotSelOrientationFront : 40|8@1+ (1,0) [0|255] ""  AP_HMI
 SG_ ParkingSlotPossOrientationFront : 32|4@1+ (1,0) [0|15] ""  AP_HMI
 SG_ ParkingSlotSelectedFront : 24|4@1+ (1,0) [0|15] ""  AP_HMI
 SG_ ParkingSlotFreeFront : 20|4@1+ (1,0) [0|15] ""  AP_HMI
 SG_ ParkingSlotScannedFront : 16|4@1+ (1,0) [0|15] ""  AP_HMI
 SG_ ParkSituationFront : 12|4@1+ (1,0) [0|15] ""  AP_HMI
 SG_ Alive_APHMIInSituationFront : 8|4@1+ (1,0) [0|15] ""  AP_HMI
 SG_ CRC_APHMIInSituationFront : 0|8@1+ (1,0) [0|255] ""  AP_HMI

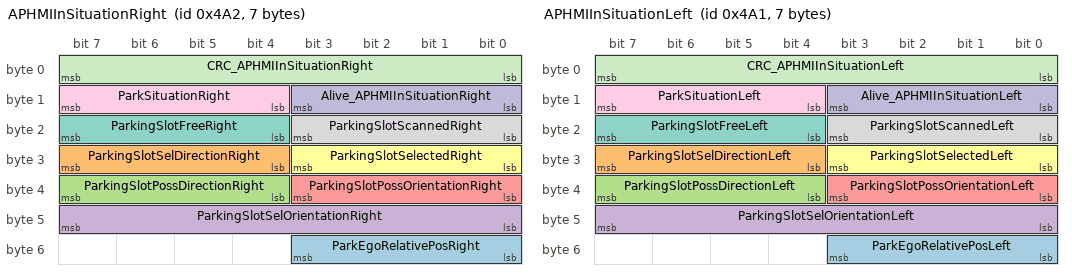
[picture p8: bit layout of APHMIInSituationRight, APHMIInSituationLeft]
BO_ 1186 APHMIInSituationRight: 7 SalvatorX
 SG_ ParkEgoRelativePosRight : 48|4@1+ (1,0) [0|15] ""  AP_HMI
 SG_ ParkingSlotSelDirectionRight : 28|4@1+ (1,0) [0|15] ""  AP_HMI
 SG_ ParkingSlotPossDirectionRight : 36|4@1+ (1,0) [0|15] ""  AP_HMI
 SG_ ParkingSlotSelOrientationRight : 40|8@1+ (1,0) [0|255] ""  AP_HMI
 SG_ ParkingSlotPossOrientationRight : 32|4@1+ (1,0) [0|15] ""  AP_HMI
 SG_ ParkingSlotSelectedRight : 24|4@1+ (1,0) [0|15] ""  AP_HMI
 SG_ ParkingSlotFreeRight : 20|4@1+ (1,0) [0|15] ""  AP_HMI
 SG_ ParkingSlotScannedRight : 16|4@1+ (1,0) [0|15] ""  AP_HMI
 SG_ ParkSituationRight : 12|4@1+ (1,0) [0|15] ""  AP_HMI
 SG_ Alive_APHMIInSituationRight : 8|4@1+ (1,0) [0|15] ""  AP_HMI
 SG_ CRC_APHMIInSituationRight : 0|8@1+ (1,0) [0|255] ""  AP_HMI

BO_ 1185 APHMIInSituationLeft: 7 SalvatorX
 SG_ ParkEgoRelativePosLeft : 48|4@1+ (1,0) [0|15] ""  AP_HMI
 SG_ ParkingSlotSelDirectionLeft : 28|4@1+ (1,0) [0|15] ""  AP_HMI
 SG_ ParkingSlotPossDirectionLeft : 36|4@1+ (1,0) [0|15] ""  AP_HMI
 SG_ ParkingSlotSelOrientationLeft : 40|8@1+ (1,0) [0|255] ""  AP_HMI
 SG_ ParkingSlotPossOrientationLeft : 32|4@1+ (1,0) [0|15] ""  AP_HMI
 SG_ ParkingSlotSelectedLeft : 24|4@1+ (1,0) [0|15] ""  AP_HMI
 SG_ ParkingSlotFreeLeft : 20|4@1+ (1,0) [0|15] ""  AP_HMI
 SG_ ParkingSlotScannedLeft : 16|4@1+ (1,0) [0|15] ""  AP_HMI
 SG_ ParkSituationLeft : 12|4@1+ (1,0) [0|15] ""  AP_HMI
 SG_ Alive_APHMIInSituationLeft : 8|4@1+ (1,0) [0|15] ""  AP_HMI
 SG_ CRC_APHMIInSituationLeft : 0|8@1+ (1,0) [0|255] ""  AP_HMI

BO_ 1184 APHMIInGeneral1: 8 SalvatorX
 SG_ APHMIGeneralRevAssistPoss : 62|1@1+ (1,0) [0|1] ""  AP_HMI
 SG_ APHMIGeneralParkInOutFinished : 45|1@1+ (1,0) [0|1] ""  AP_HMI
 SG_ APHMIGeneralRemKeyPoss : 63|1@1+ (1,0) [0|1] ""  AP_HMI
 SG_ APHMIGeneralMaxSpeed10Warning : 14|2@1+ (1,0) [0|2] ""  AP_HMI
 SG_ APHMIGeneralSemiAutomParkPoss : 13|1@1+ (1,0) [0|1] ""  AP_HMI
 SG_ APHMIGeneralFullyAutomParkPoss : 12|1@1+ (1,0) [0|1] ""  AP_HMI
 SG_ Alive_APHMIInGeneral1 : 8|4@1+ (1,0) [0|15] ""  AP_HMI
 SG_ CRC_APHMIInGeneral1 : 0|8@1+ (1,0) [0|255] ""  AP_HMI
 SG_ APHMIGeneralCurrentGear : 36|4@1+ (1,0) [0|0] ""  AP_HMI
 SG_ APHMIParkingProcedureCtrlState : 40|5@1+ (1,0) [0|0] ""  AP_HMI
 SG_ APHMIGeneralAVGType : 32|4@1+ (1,0) [0|0] ""  AP_HMI
 SG_ APHMIGeneralDrivingDir : 22|2@1+ (1,0) [0|0] ""  AP_HMI
 SG_ APHMIGeneralDistToStop : 24|8@1+ (0.4,0) [0|0] "%"  AP_HMI
 SG_ APHMIGeneralBtnForwardPoss : 20|1@1+ (1,0) [0|0] ""  AP_HMI
 SG_ APHMIGeneralBtnBackwardPoss : 21|1@1+ (1,0) [0|0] ""  AP_HMI
 SG_ APHMIGeneralSVPoss : 55|1@1+ (1,0) [0|0] ""  AP_HMI
 SG_ APHMIGeneralUndoPoss : 18|1@1+ (1,0) [0|0] ""  AP_HMI
 SG_ APHMIGeneralRemManPoss : 54|1@1+ (1,0) [0|0] ""  AP_HMI
 SG_ APHMIGeneralParkOutPoss : 16|1@1+ (1,0) [0|0] ""  AP_HMI
 SG_ APHMIGeneralParkInPoss : 17|1@1+ (1,0) [0|0] ""  AP_HMI
 SG_ APHMIGeneralContinuePoss : 19|1@1+ (1,0) [0|0] ""  AP_HMI
 SG_ APHMIGeneralRemCtrlPoss : 53|1@1+ (1,0) [0|0] ""  AP_HMI
 SG_ APHMIGeneralRemCtrlSelected : 47|1@1+ (1,0) [0|0] ""  AP_HMI
 SG_ APHMIGeneralRemAppActive : 46|1@1+ (1,0) [0|0] ""  AP_HMI
 SG_ APHMIGeneralMessage : 56|6@1+ (1,0) [0|0] ""  AP_HMI
 SG_ APHMIGeneralScreen : 48|5@1+ (1,0) [0|0] ""  AP_HMI

BO_ 509 ContiGuardUSS_Control: 2 SalvatorX
 SG_ FiringScheme : 8|3@1+ (1,0) [0|0] "ENUM"  CAN2LIN_GW
 SG_ EnableUltrasonic : 0|1@1+ (1,0) [0|0] "bool"  CAN2LIN_GW

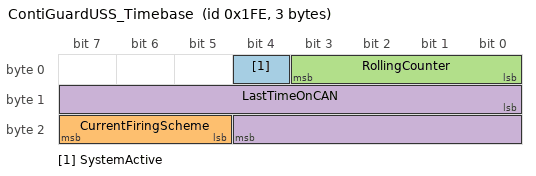
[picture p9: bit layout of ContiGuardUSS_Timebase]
BO_ 510 ContiGuardUSS_Timebase: 3 CAN2LIN_GW
 SG_ SystemActive : 4|1@1+ (1,0) [0|0] "bool"  SalvatorX
 SG_ CurrentFiringScheme : 21|3@1+ (1,0) [0|0] "ENUM"  SalvatorX
 SG_ RollingCounter : 0|4@1+ (1,0) [0|0] ""  SalvatorX
 SG_ LastTimeOnCAN : 8|13@1+ (1,0) [0|0] "ms"  SalvatorX

BO_ 511 ContiGuardUSS_Measure: 8 CAN2LIN_GW
 SG_ Multiplexer M : 0|2@1+ (1,0) [0|0] ""  SalvatorX
 SG_ Timestamp : 3|13@1+ (1,0) [0|0] "ms"  SalvatorX
 SG_ TotalNumberOfMessages : 16|2@1+ (1,1) [0|0] ""  SalvatorX
 SG_ Messagenumber : 18|2@1+ (1,1) [0|0] ""  SalvatorX
 SG_ SenderSensor : 20|4@1+ (1,0) [0|0] "ENUM"  SalvatorX
 SG_ ReceiverSensor : 24|4@1+ (1,0) [0|0] "ENUM"  SalvatorX
 SG_ Sensorstatus : 28|3@1+ (1,0) [0|0] "ENUM"  SalvatorX
 SG_ TOF1 m0 : 32|8@1+ (110,0) [0|0] "us"  SalvatorX
 SG_ TOF2 m0 : 40|8@1+ (110,0) [0|0] "us"  SalvatorX
 SG_ DURATION1 m1 : 32|8@1+ (36.75,0) [0|0] "us"  SalvatorX
 SG_ DURATION2 m1 : 40|8@1+ (36.75,0) [0|0] "us"  SalvatorX
 SG_ PEAKVALUE1 m0 : 56|8@1+ (1,0) [0|0] "nonlinear scale"  SalvatorX
 SG_ PEAKVALUE2 m0 : 48|8@1+ (1,0) [0|0] "nonlinear scale"  SalvatorX

CM_ "Version 1.11";
CM_ BO_ 3221225472 "This is a message for not used signals, created by Vector CANdb++ DBC OLE DB Provider.";
CM_ SG_ 3221225472 APHMIGeneralReserved "Obsolete signal. Kept as reserve. New signal instead: 
APHMIGeneralRemModeActive";
CM_ SG_ 1279 WhlDirectionRL "Direction of rear left wheel.";
CM_ SG_ 1279 WhlAbsAngleRL "Absolute value for the the rear left wheel angle in degrees.";
CM_ SG_ 1279 WhlAbsAngleFR "Absolute value for the the front right wheel angle in degrees.";
CM_ SG_ 1279 WhlDirectionRR "Direction of rear right wheel";
CM_ SG_ 1279 WhlDirectionFR "Direction of front right wheel.";
CM_ SG_ 1279 WhlDirectionFL "Direction of front left wheel";
CM_ SG_ 1279 WhlAbsAngleRR "Absolute value for the the rear right wheel angle in degrees.";
CM_ SG_ 1279 WhlAbsAngleFL "Absolute value for the the front left wheel angle in degrees.";
CM_ SG_ 1279 WHPDisplayReq "Display request for Wheel Protection function";
CM_ SG_ 1279 WHPState "State information for Wheel Protection function";
CM_ SG_ 1279 WhlWarningLevelRR "Warning level for rear right wheel";
CM_ SG_ 1279 WhlWarningLevelRL "Warning level for rear left wheel";
CM_ SG_ 1279 WhlWarningLevelFR "Warning level for front right wheel";
CM_ SG_ 1279 WhlWarningLevelFL "Warning level for front left wheel";
CM_ SG_ 1199 RearSpeakerOn "On/Off status of the rear speaker";
CM_ SG_ 1199 FrontSpeakerOn "On/Off status of the front speaker";
CM_ SG_ 1199 RearSpeakerVolume "Tone volume for rear speaker (0 = mute, 7 = max volume)";
CM_ SG_ 1199 FrontSpeakerVolume "Tone volume for rear speaker (0 = mute, 7 = max volume)";
CM_ SG_ 1199 RearSpeakerPitch "Tone pitch for rear speaker (range between 0-255)";
CM_ SG_ 1199 FrontSpeakerPitch "Tone pitch for front speaker (range between 0-255)";
CM_ SG_ 1198 APHMIOutRemScreenResY "Screen resolution of remote device y-direction";
CM_ SG_ 1198 APHMIOutRemScreenResX "Screen resolution of remote device x-direction";
CM_ SG_ 1197 APHMIOutGesture_Counter "Wrap-around counter for gesture signal (will be increased with every gesture event).";
CM_ SG_ 1197 APHMIOutGesture_FingerCount "Numbers of fingers touching the display.";
CM_ SG_ 1197 APHMIOutGesture_Code "Gesture Code identifies which kind of gesture was done by the user. Keeps the value of the last gesture that took place. New event occurance is determined by an increase in the gesture counter.";
CM_ SG_ 1197 APHMIOutGesture_YPos "This signals holds the y position of the gesture.";
CM_ SG_ 1197 APHMIOutGesture_XPos "This signals holds the x position of the gesture.";
CM_ BO_ 193 "It's additionally sent on_event
";
CM_ SG_ 193 KeyFobInRange "Key is in the range to control the vehicle
In an initial Version (Apr. 2018) only OUT_OF_RANGE and NEAR_RANGE wil be used. No detection of IN_VEHICLE or difference between NEAR_RANGE and FAR_RANGE";
CM_ SG_ 193 KeyFobMovementButtonAlive "Will be increased by one each time the key communicates with HFM ( when the key is in the range)";
CM_ SG_ 193 KeyFobUserAction "User interaction with HMI (Head Unit)";
CM_ BO_ 752 "Used versions of dbc files for CANs and GWs";
CM_ SG_ 752 CONTI_CANVersionMayor "Minor version of CONTI-CAN";
CM_ SG_ 752 CONTI_CANVersionMinor "Minor version of CONTI-CAN";
CM_ SG_ 752 APprivateCANVersionMayor "Mayor version of AP_private_CAN";
CM_ SG_ 752 APprivateCANVersionMinor "Minor version of AP_private_CAN";
CM_ SG_ 1196 APHMIOutBTDevConnected "True if bluetooth devoce is connected";
CM_ SG_ 1196 APHMIOutBTDevPaired "True if bluetooth device is paired";
CM_ SG_ 1196 APHMIOutRemFingerPosY "y Finger position on Smartphone display
4095: Finger is not on screen (0xfff)";
CM_ SG_ 1196 APHMIOutRemFingerPosX "x Finger position on Smartphone display
4095: Finger is not on screen (0xfff)";
CM_ SG_ 1196 APHMIOutRemAlive "Increases on each cycle by one. To ensure the connection betwenn vehicle and mobile device is alive.";
CM_ SG_ 1195 APHMIInSlotUnreachReason "Describes the reason why the selected slot is not reachable, when the user selects an unreachable pose.";
CM_ SG_ 1195 APHMIInMemorizedPoseSlotId "Indicates the memory slot id that stores the redetected memorized pose.";
CM_ SG_ 1195 APHMIInMemorySlotsStatus "Bitarray indicating which of the memory slots are occupied (bit X = 1 means slot X contains a memorized user defined pose).";
CM_ SG_ 1195 APHMIInDisplayBackButton "Indicates if the back button should be displayed. Purpose of the button is to allow the user to go back to top view from the 3D view that is displayed once a slot was selected by the user.";
CM_ SG_ 1195 APHMIMemorizedPoseYaw "Describes the absolute value of the yaw angle for the redetected memorized pose. To be used by the HMI to correctly display the rotation angle of the pose.";
CM_ SG_ 1195 APHMIMemorizedPoseYawSign "Describes the sign of the yaw angle for the redetected memorized pose (0 = POSITIVE, 1 = NEGATIVE). To be used by the HMI to correctly display the rotation angle of the pose.";
CM_ SG_ 1195 APHMIGeneralMemParkPoss "True, if memory parking mode is possible. (In this case, user can select it via memory parking mode button)";
CM_ SG_ 1195 APHMIGeneralRemModeActive " Indicates the currently active mode of AP related to remote functionality";
CM_ SG_ 1195 APHMIInGarageParkingState "This signal contains the information about the garage parking maneuver state.";
CM_ SG_ 1195 APHMIInSVScrenResponse "This signal is the output of the ViewController component.
It holds information about the currently active surround view screen.
You may use signal APHMIOutUserSVScreenRequest to request view changes by the HMI.";
CM_ SG_ 1195 APHMIInStreamAvailable "Signal is the output of the ViewController component.
True means a surround view stream is visible.
False means no stream is visible.";
CM_ SG_ 1195 APHMIGeneralScreenRemote "HMI screen content depending on system status";
CM_ SG_ 1195 APHMIGeneralMessageRemote "Message to show on screen";
CM_ SG_ 380 CRC_CLU_ID7 "Polynom: x^8 + x^4 + x^3 + x^2 + 1";
CM_ SG_ 376 Longitudinal_acceleration "Signal multiplied by -1 to match the mounting position in Passat B8";
CM_ SG_ 376 Roll_rate "Signal multiplied by -1 to match the mounting position in Passat B8";
CM_ SG_ 376 Diagnosis_code_cluster "This signal transmits the diagnostic data of the sensorcluster. The signal 'diagnosis_counter_cluster' of the message 'SYNC_CLU' is used for selecting the required information.";
CM_ SG_ 376 CRC_CLU_ID4 "Polynom: x^8 + x^4 + x^3 + x^2 + 1";
CM_ SG_ 372 Yaw_rate "Signal multiplied by -1 to match the mounting position in Passat B8";
CM_ SG_ 372 Lateral_acceleration "Signal multiplied by -1 to match the mounting position in Passat B8";
CM_ SG_ 372 CRC_CLU_ID1 "Polynom: x^8 + x^4 + x^3 + x^2 + 1";
CM_ SG_ 1189 APHMIOutBlindSpotActivated "True if blind spot views setting is ON (the blind spot views will get activated by the turn signal).";
CM_ SG_ 1189 APHMIOutUserActionRemCounter "Number of remote device user actions. This counter will be increased with any remote user action event.";
CM_ SG_ 1189 APHMIOutUserActionHUCounter "Number of head unit(HU) user actions. This counter will be increased with any  head unit user action events.";
CM_ SG_ 1189 APHMIOutUserSVScreenRequest "request from HMI to show specific camera stream";
CM_ SG_ 1189 APHMIOutUserActionRem "User interaction with HMI (Remote Device)";
CM_ SG_ 1189 APHMIOutScreenRem "Shown AP Screen on Remote Device";
CM_ SG_ 1189 APHMIOutBatteryLevelRem "Returns battery level of remote device to ensure enough usage time of the remote device for parking function";
CM_ SG_ 1189 APHMIOutScreenHU "Shown AP Screen on Head Unit";
CM_ SG_ 1189 APHMIOutUserActionHU "User interaction with HMI (Head Unit)";
CM_ SG_ 1194 ParkDistViewHigh40 "The surrounding of the vehicle is devided into 40 segments clockwise.
Each segment is divided into 7 bars, representing the distance.
 Calc of Segment in deg:
- Start of segment: (1-SegNr)*9
- End of segment: (SegNr)*9
";
CM_ SG_ 1194 ParkDistViewHigh39 "The surrounding of the vehicle is devided into 40 segments clockwise.
Each segment is divided into 7 bars, representing the distance.
 Calc of Segment in deg:
- Start of segment: (1-SegNr)*9
- End of segment: (SegNr)*9
";
CM_ SG_ 1194 ParkDistViewHigh38 "The surrounding of the vehicle is devided into 40 segments clockwise.
Each segment is divided into 7 bars, representing the distance.
 Calc of Segment in deg:
- Start of segment: (1-SegNr)*9
- End of segment: (SegNr)*9
";
CM_ SG_ 1194 ParkDistViewHigh37 "The surrounding of the vehicle is devided into 40 segments clockwise.
Each segment is divided into 7 bars, representing the distance.
 Calc of Segment in deg:
- Start of segment: (1-SegNr)*9
- End of segment: (SegNr)*9
";
CM_ SG_ 1194 ParkDistViewHigh36 "The surrounding of the vehicle is devided into 40 segments clockwise.
Each segment is divided into 7 bars, representing the distance.
 Calc of Segment in deg:
- Start of segment: (1-SegNr)*9
- End of segment: (SegNr)*9
";
CM_ SG_ 1194 ParkDistViewHigh35 "The surrounding of the vehicle is devided into 40 segments clockwise.
Each segment is divided into 7 bars, representing the distance.
 Calc of Segment in deg:
- Start of segment: (1-SegNr)*9
- End of segment: (SegNr)*9
";
CM_ SG_ 1194 ParkDistViewHigh34 "The surrounding of the vehicle is devided into 40 segments clockwise.
Each segment is divided into 7 bars, representing the distance.
 Calc of Segment in deg:
- Start of segment: (1-SegNr)*9
- End of segment: (SegNr)*9
";
CM_ SG_ 1194 ParkDistViewHigh33 "The surrounding of the vehicle is devided into 40 segments clockwise.
Each segment is divided into 7 bars, representing the distance.
 Calc of Segment in deg:
- Start of segment: (1-SegNr)*9
- End of segment: (SegNr)*9
";
CM_ SG_ 1194 ParkDistViewHigh32 "The surrounding of the vehicle is devided into 40 segments clockwise.
Each segment is divided into 7 bars, representing the distance.
 Calc of Segment in deg:
- Start of segment: (1-SegNr)*9
- End of segment: (SegNr)*9
";
CM_ SG_ 1194 ParkDistViewHigh31 "The surrounding of the vehicle is devided into 40 segments clockwise.
Each segment is divided into 7 bars, representing the distance.
 Calc of Segment in deg:
- Start of segment: (1-SegNr)*9
- End of segment: (SegNr)*9
";
CM_ SG_ 1193 PDCRear1IntersectDrvTube "Indicates if the obstacle that determines the criticality of this sector intersects the driving tube";
CM_ SG_ 1193 PDCRear1Slice "Slice number within the criticality level (numbering is done from the outside of the car towards the car contour).";
CM_ SG_ 1193 PDCRear1CriticalLevel "Criticality level for this sector (the higher the criticality, the closer the obstacle is to the car).";
CM_ SG_ 1193 PDCRear2IntersectDrvTube "Indicates if the obstacle that determines the criticality of this sector intersects the driving tube";
CM_ SG_ 1193 PDCRear2Slice "Slice number within the criticality level (numbering is done from the outside of the car towards the car contour).";
CM_ SG_ 1193 PDCRear2CriticalLevel "Criticality level for this sector (the higher the criticality, the closer the obstacle is to the car).";
CM_ SG_ 1193 PDCRear3IntersectDrvTube "Indicates if the obstacle that determines the criticality of this sector intersects the driving tube";
CM_ SG_ 1193 PDCRear3Slice "Slice number within the criticality level (numbering is done from the outside of the car towards the car contour).";
CM_ SG_ 1193 PDCRear3CriticalLevel "Criticality level for this sector (the higher the criticality, the closer the obstacle is to the car).";
CM_ SG_ 1193 PDCRear4IntersectDrvTube "Indicates if the obstacle that determines the criticality of this sector intersects the driving tube";
CM_ SG_ 1193 PDCRear4Slice "Slice number within the criticality level (numbering is done from the outside of the car towards the car contour).";
CM_ SG_ 1193 PDCRear4CriticalLevel "Criticality level for this sector (the higher the criticality, the closer the obstacle is to the car).";
CM_ SG_ 1193 PDCRight1IntersectDrvTube "Indicates if the obstacle that determines the criticality of this sector intersects the driving tube";
CM_ SG_ 1193 PDCRight1Slice "Slice number within the criticality level (numbering is done from the outside of the car towards the car contour).";
CM_ SG_ 1193 PDCRight1CriticalLevel "Criticality level for this sector (the higher the criticality, the closer the obstacle is to the car).";
CM_ SG_ 1193 PDCRight2IntersectDrvTube "Indicates if the obstacle that determines the criticality of this sector intersects the driving tube";
CM_ SG_ 1193 PDCRight2Slice "Slice number within the criticality level (numbering is done from the outside of the car towards the car contour).";
CM_ SG_ 1193 PDCRight2CriticalLevel "Criticality level for this sector (the higher the criticality, the closer the obstacle is to the car).";
CM_ SG_ 1193 PDCRight3IntersectDrvTube "Indicates if the obstacle that determines the criticality of this sector intersects the driving tube";
CM_ SG_ 1193 PDCRight3Slice "Slice number within the criticality level (numbering is done from the outside of the car towards the car contour).";
CM_ SG_ 1193 PDCRight3CriticalLevel "Criticality level for this sector (the higher the criticality, the closer the obstacle is to the car).";
CM_ SG_ 1193 PDCRight4IntersectDrvTube "Indicates if the obstacle that determines the criticality of this sector intersects the driving tube";
CM_ SG_ 1193 PDCRight4Slice "Slice number within the criticality level (numbering is done from the outside of the car towards the car contour).";
CM_ SG_ 1193 PDCRight4CriticalLevel "Criticality level for this sector (the higher the criticality, the closer the obstacle is to the car).";
CM_ SG_ 1192 PDCFront1IntersectDrvTube "Indicates if the obstacle that determines the criticality of this sector intersects the driving tube";
CM_ SG_ 1192 PDCFront1Slice "Slice number within the criticality level (numbering is done from the outside of the car towards the car contour).";
CM_ SG_ 1192 PDCFront1CriticalLevel "Criticality level for this sector (the higher the criticality, the closer the obstacle is to the car).";
CM_ SG_ 1192 PDCFront2IntersectDrvTube "Indicates if the obstacle that determines the criticality of this sector intersects the driving tube";
CM_ SG_ 1192 PDCFront2Slice "Slice number within the criticality level (numbering is done from the outside of the car towards the car contour).";
CM_ SG_ 1192 PDCFront2CriticalLevel "Criticality level for this sector (the higher the criticality, the closer the obstacle is to the car).";
CM_ SG_ 1192 PDCFront3IntersectDrvTube "Indicates if the obstacle that determines the criticality of this sector intersects the driving tube";
CM_ SG_ 1192 PDCFront3Slice "Slice number within the criticality level (numbering is done from the outside of the car towards the car contour).";
CM_ SG_ 1192 PDCFront3CriticalLevel "Criticality level for this sector (the higher the criticality, the closer the obstacle is to the car).";
CM_ SG_ 1192 PDCFront4IntersectDrvTube "Indicates if the obstacle that determines the criticality of this sector intersects the driving tube";
CM_ SG_ 1192 PDCFront4Slice "Slice number within the criticality level (numbering is done from the outside of the car towards the car contour).";
CM_ SG_ 1192 PDCFront4CriticalLevel "Criticality level for this sector (the higher the criticality, the closer the obstacle is to the car).";
CM_ SG_ 1192 PDCLeft1IntersectDrvTube "Indicates if the obstacle that determines the criticality of this sector intersects the driving tube";
CM_ SG_ 1192 PDCLeft1Slice "Slice number within the criticality level (numbering is done from the outside of the car towards the car contour).";
CM_ SG_ 1192 PDCLeft1CriticalLevel "Criticality level for this sector (the higher the criticality, the closer the obstacle is to the car).";
CM_ SG_ 1192 PDCLeft2IntersectDrvTube "Indicates if the obstacle that determines the criticality of this sector intersects the driving tube";
CM_ SG_ 1192 PDCLeft2Slice "Slice number within the criticality level (numbering is done from the outside of the car towards the car contour).";
CM_ SG_ 1192 PDCLeft2CriticalLevel "Criticality level for this sector (the higher the criticality, the closer the obstacle is to the car).";
CM_ SG_ 1192 PDCLeft3IntersectDrvTube "Indicates if the obstacle that determines the criticality of this sector intersects the driving tube";
CM_ SG_ 1192 PDCLeft3Slice "Slice number within the criticality level (numbering is done from the outside of the car towards the car contour).";
CM_ SG_ 1192 PDCLeft3CriticalLevel "Criticality level for this sector (the higher the criticality, the closer the obstacle is to the car).";
CM_ SG_ 1192 PDCLeft4IntersectDrvTube "Indicates if the obstacle that determines the criticality of this sector intersects the driving tube";
CM_ SG_ 1192 PDCLeft4Slice "Slice number within the criticality level (numbering is done from the outside of the car towards the car contour).";
CM_ SG_ 1192 PDCLeft4CriticalLevel "Criticality level for this sector (the higher the criticality, the closer the obstacle is to the car).";
CM_ SG_ 1191 DrivingTubeDirection "Driving tube direction";
CM_ SG_ 1191 DrivingTubeDisplay "Side where the driving tube should be displayed";
CM_ SG_ 1191 DrivingTubeRearRadius "Radius of the driving tube on the rear. 
0..65533: valid radius values
65534: infinite (straight driving tube should be displayed)
65535: unknown (driving tube cannot be determined)";
CM_ SG_ 1191 DrivingTubeFrontRadius "Radius of the driving tube on the front. 
0..65533: valid radius values
65534: infinite (straight driving tube should be displayed)
65535: unknown (driving tube cannot be determined)";
CM_ SG_ 1191 PDCShutdownCause "PDC shutdown cause in case PDC system state is off ";
CM_ SG_ 1191 PDCSystemState "PDC system state info";
CM_ SG_ 1190 USSDistanceFrontCenterLeft "Information of USS Front Center Left";
CM_ SG_ 1190 USSDistanceFrontLeft "Information of USS Front Left";
CM_ SG_ 1190 USSDistanceSideFrontLeft "Information of USS Side Front Left";
CM_ SG_ 1190 USSDistanceSideRearLeft "Information of USS Side Rear Left";
CM_ SG_ 1190 USSDistanceRearLeft "Information of USS Rear Left";
CM_ SG_ 1190 USSDistanceRearCenterLeft "Information of USS Rear Center Left";
CM_ SG_ 1190 USSDistanceRearCenterRight "Information of USS Rear Center Right";
CM_ SG_ 1190 USSDistanceRearRight "Information of USS Rear Right";
CM_ SG_ 1190 USSDistanceSideRearRight "Information of USS Side Rear Right";
CM_ SG_ 1190 USSDistanceSideFrontRight "Information of USS Side Front Right";
CM_ SG_ 1190 USSDistanceFrontRight "Information of USS Front Right";
CM_ SG_ 1190 USSDistanceFrontCenterRight "Information of USS Front Center Right";
CM_ SG_ 1188 ParkingSlotSelDirectionRear "Bit-coded information, which direction was chosen by the driver. FORWARDS = 0; BACKWARDS = 1";
CM_ SG_ 1188 ParkingSlotPossDirectionRear "Bit-coded information, which direction is possible for the chosen parking slot. ONE_DIRECTION = 0; BOTH_DIRECTION = 1";
CM_ SG_ 1188 ParkingSlotSelOrientationRear "Bit-coded information, which orientation  was chosen by the driver in uncertain situation. PARALLEL = 0; PERPENDICULAR = 1; ANGLED_STANDARD = 2; ANGLED_REVERSE = 3";
CM_ SG_ 1188 ParkingSlotPossOrientationRear "Bit-coded information, if parking slot is uncertain. CERTAIN = 0; UNCERTAIN = 1";
CM_ SG_ 1188 ParkingSlotSelectedRear "Bit-coded information, if parking slot is selected by driver";
CM_ SG_ 1188 ParkingSlotFreeRear "Bit-coded free-status of four parking slots";
CM_ SG_ 1188 ParkingSlotScannedRear "Bit-coded scanning status of four parking slots";
CM_ SG_ 1187 ParkingSlotSelDirectionFront "Bit-coded information, which direction was chosen by the driver. FORWARDS = 0; BACKWARDS = 1";
CM_ SG_ 1187 ParkingSlotPossDirectionFront "Bit-coded information, which direction is possible for the chosen parking slot. ONE_DIRECTION = 0; BOTH_DIRECTION = 1";
CM_ SG_ 1187 ParkingSlotSelOrientationFront "Bit-coded information, which orientation  was chosen by the driver in uncertain situation. PARALLEL = 0; PERPENDICULAR = 1; ANGLED_STANDARD = 2; ANGLED_REVERSE = 3";
CM_ SG_ 1187 ParkingSlotPossOrientationFront "Bit-coded information, if parking slot is uncertain. CERTAIN = 0; UNCERTAIN = 1";
CM_ SG_ 1187 ParkingSlotSelectedFront "Bit-coded information, if parking slot is selected by driver";
CM_ SG_ 1187 ParkingSlotFreeFront "Bit-coded free-status of four parking slots";
CM_ SG_ 1187 ParkingSlotScannedFront "Bit-coded scanning status of four parking slots";
CM_ SG_ 1186 ParkEgoRelativePosRight "Ego vehicle rear axle position, relative to the right parking slots. 
0 = rear axle is one slot width ahead of the top most slot shown in HMI (reference position). 
Increment 1 means half a slot width further down (behind) the reference position.";
CM_ SG_ 1186 ParkingSlotSelDirectionRight "Bit-coded information, which direction was chosen by the driver. FORWARDS = 0; BACKWARDS = 1";
CM_ SG_ 1186 ParkingSlotPossDirectionRight "Bit-coded information, which direction is possible for the chosen parking slot. ONE_DIRECTION = 0; BOTH_DIRECTION = 1";
CM_ SG_ 1186 ParkingSlotSelOrientationRight "Bit-coded information, which orientation  was chosen by the driver in uncertain situation. PARALLEL = 0; PERPENDICULAR = 1; ANGLED_STANDARD = 2; ANGLED_REVERSE = 3";
CM_ SG_ 1186 ParkingSlotPossOrientationRight "Bit-coded information, if parking slot is uncertain. CERTAIN = 0; UNCERTAIN = 1";
CM_ SG_ 1186 ParkingSlotSelectedRight "Bit-coded information, if parking slot is selected by driver";
CM_ SG_ 1186 ParkingSlotFreeRight "Bit-coded free-status of four parking slots";
CM_ SG_ 1186 ParkingSlotScannedRight "Bit-coded scanning status of four parking slots";
CM_ SG_ 1185 ParkEgoRelativePosLeft "Ego vehicle rear axle position, relative to the left parking slots. 
0 = rear axle is one slot width ahead of the top most slot shown in HMI (reference position). 
Increment 1 means half a slot width further down (behind) the reference position.";
CM_ SG_ 1185 ParkingSlotSelDirectionLeft "Bit-coded information, which direction was chosen by the driver. FORWARDS = 0; BACKWARDS = 1";
CM_ SG_ 1185 ParkingSlotPossDirectionLeft "Bit-coded information, which direction is possible for the chosen parking slot. ONE_DIRECTION = 0; BOTH_DIRECTION = 1";
CM_ SG_ 1185 ParkingSlotSelOrientationLeft "Bit-coded information, which orientation  was chosen by the driver in uncertain situation. PARALLEL = 0; PERPENDICULAR = 1; ANGLED_STANDARD = 2; ANGLED_REVERSE = 3";
CM_ SG_ 1185 ParkingSlotPossOrientationLeft "Bit-coded information, if parking slot is uncertain. CERTAIN = 0; UNCERTAIN = 1";
CM_ SG_ 1185 ParkingSlotSelectedLeft "Bit-coded information, if parking slot is selected by driver";
CM_ SG_ 1185 ParkingSlotFreeLeft "Bit-coded free-status of four parking slots";
CM_ SG_ 1185 ParkingSlotScannedLeft "Bit-coded scanning status of four parking slots";
CM_ SG_ 1184 APHMIGeneralRevAssistPoss "True, if reverse assist is possible. (In this case, user can select it via reverse assist button)";
CM_ SG_ 1184 APHMIGeneralParkInOutFinished "Is TRUE (1) when the Park In or Park Out naneuver was finished
Is FALSE (0) elswhere";
CM_ SG_ 1184 APHMIGeneralRemKeyPoss "Signal is 1 (TRUE)  if AP allows remote by Key";
CM_ SG_ 1184 APHMIGeneralMaxSpeed10Warning "Information if the max speed sign in HMI must be shown continuously or blinking";
CM_ SG_ 1184 APHMIGeneralSemiAutomParkPoss "True if the semi (only LateralControl) automated Parking algorithm is available";
CM_ SG_ 1184 APHMIGeneralFullyAutomParkPoss "True if the fully automated Parking algorithm is available";
CM_ SG_ 1184 APHMIGeneralCurrentGear "Current gear of the ego vehicle. This information is displayed in automated vehicle guidance (AVG) mode.";
CM_ SG_ 1184 APHMIParkingProcedureCtrlState "Current State of the parking procedure state machine";
CM_ SG_ 1184 APHMIGeneralAVGType "Shows the simplified situation during Automated Vehicle Guidance to enable HMI to inform driver of maneuver.";
CM_ SG_ 1184 APHMIGeneralDrivingDir "Vehicle direction for the current maneuver part";
CM_ SG_ 1184 APHMIGeneralDistToStop "Distance to next stopping point during parking maneuver in percent (could be shown in a filling bar)";
CM_ SG_ 1184 APHMIGeneralBtnForwardPoss "[for Remote Maneuvering]True, if it is possible to move the ego vehicle in forward direction -> Forward-Button is active in REM_MAN-Screen";
CM_ SG_ 1184 APHMIGeneralBtnBackwardPoss "[for Remote Maneuvering]True, if it is possible to move the ego vehicle in backward direction -> Backward-Button is active in REM_MAN-Screen";
CM_ SG_ 1184 APHMIGeneralSVPoss "True, if the vehicle can stream a surround-view view to the remote parking app";
CM_ SG_ 1184 APHMIGeneralUndoPoss "Indicates wether it is possible to undo the interrupted maneuver";
CM_ SG_ 1184 APHMIGeneralRemManPoss "True, if remote maneuvering is possible. (In this case, user can select it via menu of the remote parking app)";
CM_ SG_ 1184 APHMIGeneralParkOutPoss "True, if remote parking out is possible. (In this case, user can select it via menu of the remote parking app";
CM_ SG_ 1184 APHMIGeneralParkInPoss "True, if remote parking in is possible. (In this case, user can select it via menu of the remote parking app)";
CM_ SG_ 1184 APHMIGeneralContinuePoss "Indicates wether it is possible to continue the interrupted maneuver";
CM_ SG_ 1184 APHMIGeneralRemCtrlPoss "Indicates, whether Remote Control is possible in the vehicle";
CM_ SG_ 1184 APHMIGeneralRemCtrlSelected "True if user selected Remote Control instead of in vehicle parking";
CM_ SG_ 1184 APHMIGeneralRemAppActive "Indicates, whether the Remote App is active (= is opened and is not breaked down)";
CM_ SG_ 1184 APHMIGeneralMessage "Message to show on screen";
CM_ SG_ 1184 APHMIGeneralScreen "HMI screen content depending on system status";
CM_ SG_ 509 FiringScheme "select, which firing scheme the ECU should use";
CM_ SG_ 509 EnableUltrasonic "Activae/Deactivate the USS system";
CM_ SG_ 510 SystemActive "True if the Ultrasonic system performs measurements, false when paused";
CM_ SG_ 511 PEAKVALUE1 "from COBRA specification: If bits in range 0 .. 127 = bits * 8mV 	If bits in range 128 .. 255 = bits * 16mV – 1024mV";
CM_ SG_ 511 PEAKVALUE2 "from COBRA specification: If bits in range 0 .. 127 = bits * 8mV 	If bits in range 128 .. 255 = bits * 16mV – 1024mV";
BA_DEF_  "BusType" STRING ;
BA_DEF_  "Version" HEX 0 255;
BA_DEF_  "NmMessageCount" INT 0 64;
BA_DEF_  "NWID" HEX 0 255;
BA_DEF_  "NBTMax" INT 0 255;
BA_DEF_  "NBTMin" INT 0 255;
BA_DEF_  "SamplePointMax" FLOAT 0 100;
BA_DEF_  "SamplePointMin" FLOAT 0 100;
BA_DEF_  "NWM-Basisadresse" HEX 0 536870911;
BA_DEF_  "NWM-Typ" ENUM  "zentral (MB-W210)","dezentral (MB-OSAN)","keines","VAG-OSEK","BMW-OSEK","PAG-OSEK","DBAG-OSEK";
BA_DEF_ SG_  "GenSigStartValue" HEX 0 4294967295;
BA_DEF_ BO_  "GenMsgCycleTime" INT 0 65535;
BA_DEF_ BO_  "GenMsgSendType" ENUM  "cyclicX","spontanX","cyclicIfActiveX","spontanWithDelay","cyclicAndSpontanX","cyclicAndSpontanWithDelay","spontanWithRepitition","cyclicIfActiveAndSpontanWD","cyclicIfActiveFast","cyclicWithRepeatOnDemand","none";
BA_DEF_  "Baudrate" INT 0 1000000;
BA_DEF_  "VersionWeek" INT 0 53;
BA_DEF_  "VersionYear" INT 0 99;
BA_DEF_  "Manufacturer" ENUM  "DBAG","VAG","BMWAG","PAG","GM";
BA_DEF_DEF_  "BusType" "";
BA_DEF_DEF_  "Version" 192;
BA_DEF_DEF_  "NmMessageCount" 64;
BA_DEF_DEF_  "NWID" 11;
BA_DEF_DEF_  "NBTMax" 21;
BA_DEF_DEF_  "NBTMin" 9;
BA_DEF_DEF_  "SamplePointMax" 81.25;
BA_DEF_DEF_  "SamplePointMin" 75;
BA_DEF_DEF_  "NWM-Basisadresse" 1024;
BA_DEF_DEF_  "NWM-Typ" "keines";
BA_DEF_DEF_  "GenSigStartValue" 0;
BA_DEF_DEF_  "GenMsgCycleTime" 0;
BA_DEF_DEF_  "GenMsgSendType" "";
BA_DEF_DEF_  "Baudrate" 500000;
BA_DEF_DEF_  "VersionWeek" 28;
BA_DEF_DEF_  "VersionYear" 6;
BA_DEF_DEF_  "Manufacturer" "DBAG";
BA_ "BusType" "CAN";
BA_ "GenMsgSendType" BO_ 1279 0;
BA_ "GenMsgCycleTime" BO_ 1279 100;
BA_ "GenMsgCycleTime" BO_ 1199 100;
BA_ "GenMsgSendType" BO_ 1199 0;
BA_ "GenMsgCycleTime" BO_ 1198 100;
BA_ "GenMsgSendType" BO_ 1198 0;
BA_ "GenMsgCycleTime" BO_ 1197 100;
BA_ "GenMsgSendType" BO_ 1197 0;
BA_ "GenMsgSendType" BO_ 193 0;
BA_ "GenMsgCycleTime" BO_ 193 100;
BA_ "GenMsgSendType" BO_ 752 0;
BA_ "GenMsgCycleTime" BO_ 752 10000;
BA_ "GenMsgCycleTime" BO_ 1196 100;
BA_ "GenMsgSendType" BO_ 1196 0;
BA_ "GenMsgCycleTime" BO_ 1195 100;
BA_ "GenMsgSendType" BO_ 1195 0;
BA_ "GenMsgCycleTime" BO_ 380 10;
BA_ "GenMsgSendType" BO_ 380 0;
BA_ "GenMsgCycleTime" BO_ 376 10;
BA_ "GenMsgSendType" BO_ 376 0;
BA_ "GenMsgSendType" BO_ 372 0;
BA_ "GenMsgCycleTime" BO_ 372 10;
BA_ "GenMsgCycleTime" BO_ 1189 100;
BA_ "GenMsgSendType" BO_ 1189 0;
BA_ "GenMsgCycleTime" BO_ 1194 100;
BA_ "GenMsgSendType" BO_ 1194 0;
BA_ "GenMsgCycleTime" BO_ 1193 100;
BA_ "GenMsgSendType" BO_ 1193 0;
BA_ "GenMsgCycleTime" BO_ 1192 100;
BA_ "GenMsgSendType" BO_ 1192 0;
BA_ "GenMsgCycleTime" BO_ 1191 100;
BA_ "GenMsgSendType" BO_ 1191 0;
BA_ "GenMsgCycleTime" BO_ 1190 100;
BA_ "GenMsgSendType" BO_ 1190 0;
BA_ "GenMsgCycleTime" BO_ 1188 100;
BA_ "GenMsgSendType" BO_ 1188 0;
BA_ "GenMsgCycleTime" BO_ 1187 100;
BA_ "GenMsgSendType" BO_ 1187 0;
BA_ "GenMsgCycleTime" BO_ 1186 100;
BA_ "GenMsgSendType" BO_ 1186 0;
BA_ "GenMsgCycleTime" BO_ 1185 100;
BA_ "GenMsgSendType" BO_ 1185 0;
BA_ "GenMsgCycleTime" BO_ 1184 100;
BA_ "GenMsgSendType" BO_ 1184 0;
BA_ "GenSigStartValue" SG_ 752 APprivateCANVersionMayor 1;
BA_ "GenSigStartValue" SG_ 752 APprivateCANVersionMinor 30;
BA_ "GenSigStartValue" SG_ 1196 APHMIOutRemFingerPosY 4095;
BA_ "GenSigStartValue" SG_ 1196 APHMIOutRemFingerPosX 4095;
BA_ "GenSigStartValue" SG_ 380 Vertical_acceleration 32750;
BA_ "GenSigStartValue" SG_ 380 Pitch_rate 32768;
BA_ "GenSigStartValue" SG_ 376 Longitudinal_acceleration 32750;
BA_ "GenSigStartValue" SG_ 376 Roll_rate 32768;
BA_ "GenSigStartValue" SG_ 372 Yaw_rate 32768;
BA_ "GenSigStartValue" SG_ 372 Lateral_acceleration 32750;
BA_ "GenSigStartValue" SG_ 1189 APHMIOutBatteryLevelRem 255;
VAL_ 1279 WhlDirectionRL 1 "RIGHT" 0 "LEFT" ;
VAL_ 1279 WhlDirectionRR 1 "RIGHT" 0 "LEFT" ;
VAL_ 1279 WhlDirectionFR 1 "RIGHT" 0 "LEFT" ;
VAL_ 1279 WhlDirectionFL 1 "RIGHT" 0 "LEFT" ;
VAL_ 1279 WHPState 3 "FAILURE" 2 "ACTIVE" 1 "INACTIVE" 0 "INIT" ;
VAL_ 1279 WhlWarningLevelRR 3 "HIGH_WARNING" 2 "LOW_WARNING" 1 "NO_WARNING" 0 "NOT_AVAILABLE" ;
VAL_ 1279 WhlWarningLevelRL 3 "HIGH_WARNING" 2 "LOW_WARNING" 1 "NO_WARNING" 0 "NOT_AVAILABLE" ;
VAL_ 1279 WhlWarningLevelFR 3 "HIGH_WARNING" 2 "LOW_WARNING" 1 "NO_WARNING" 0 "NOT_AVAILABLE" ;
VAL_ 1279 WhlWarningLevelFL 3 "HIGH_WARNING" 2 "LOW_WARNING" 1 "NO_WARNING" 0 "NOT_AVAILABLE" ;
VAL_ 1197 APHMIOutGesture_Code 12 "FLICK" 31 "INVALID" 11 "TRIPLE_CLICK" 10 "DOUBLE_CLICK" 9 "RAW" 8 "ROTATE" 7 "ZOOM" 6 "DRAG" 5 "RIGHT_CLICK" 4 "CLICK" 3 "RELEASE" 2 "LONG_PRESS" 1 "PRESS" 0 "NO_ACTION" ;
VAL_ 193 KeyFobInRange 3 "FAR_RANGE" 2 "NEAR_RANGE" 1 "IN_VEHICLE" 0 "OUT_OF_RANGE" ;
VAL_ 193 KeyFobUserAction 36 "KEY_ACTIVATED" 35 "MANEUVER_PAUSED" 34 "MANEUVER_ABORTED" 33 "MANEUVER_AUTHORIZED" 32 "TAP_ON_START_REM_PARK_KEY" 31 "TAP_ON_SEMI_AUTOMATED_PARKING" 30 "TAP_ON_FULLY_AUTOMATED_PARKING" 29 "TAP_ON_LSCA_RELEASE_BRAKE" 0 "NO_USER_ACTION" 1 "TAP_ON_PARKING_SPACE_LEFT_1" 2 "TAP_ON_PARKING_SPACE_LEFT_2" 3 "TAP_ON_PARKING_SPACE_LEFT_3" 4 "TAP_ON_PARKING_SPACE_LEFT_4" 5 "TAP_ON_PARKING_SPACE_RIGHT_1" 6 "TAP_ON_PARKING_SPACE_RIGHT_2" 7 "TAP_ON_PARKING_SPACE_RIGHT_3" 8 "TAP_ON_PARKING_SPACE_RIGHT_4" 9 "TAP_ON_PARKING_SPACE_FRONT_1" 10 "TAP_ON_PARKING_SPACE_FRONT_2" 11 "TAP_ON_PARKING_SPACE_FRONT_3" 12 "TAP_ON_PARKING_SPACE_FRONT_4" 13 "TAP_ON_PARKING_SPACE_REAR_1" 14 "TAP_ON_PARKING_SPACE_REAR_2" 15 "TAP_ON_PARKING_SPACE_REAR_3" 16 "TAP_ON_PARKING_SPACE_REAR_4" 17 "TAP_ON_START_SELECTION" 18 "TAP_ON_START_PARKING" 19 "TAP_ON_INTERRUPT" 20 "TAP_ON_CONTINUE" 21 "TAP_ON_UNDO" 22 "TAP_ON_CANCEL" 23 "TAP_ON_REDO" 24 "TAP_ON_START_REM_PARK_PHONE" 25 "TAP_ON_SWITCH_DIRECTION" 26 "TAP_ON_SWITCH_ORIENTATION" 27 "TAP_ON_PREVIOUS_SCREEN" 28 "TOGGLE_AP_ACTIVE" ;
VAL_ 1196 APHMIOutBTDevConnected 0 "FALSE" 1 "TRUE" ;
VAL_ 1196 APHMIOutBTDevPaired 0 "FALSE" 1 "TRUE" ;
VAL_ 1195 APHMIInSlotUnreachReason 4 "NO_PATH_FOUND" 3 "SLOT_EXCEEDS_MAX_PB" 2 "SLOT_TOO_SHORT" 1 "SLOT_TOO_NARROW" 0 "NO_UNREACHABLE_REASON" ;
VAL_ 1195 APHMIMemorizedPoseYawSign 1 "NEGATIVE" 0 "POSITIVE" ;
VAL_ 1195 APHMIGeneralMemParkPoss 1 "TRUE" 0 "FALSE" ;
VAL_ 1195 APHMIGeneralRemModeActive 3 "REM_MODE_PARK_MAN" 2 "REM_MODE_PARK_OUT" 1 "REM_MODE_PARK_IN" 0 "REM_MODE_INACTIVE" ;
VAL_ 1195 APHMIInGarageParkingState 6 "GP_IN_DETECTED_BWD" 5 "GP_IN_DETECTED_FWD" 4 "GP_OUT_BWD" 3 "GP_OUT_FWD" 2 "GP_IN_SCAN_BWD" 1 "GP_IN_SCAN_FWD" 0 "GP_NOT_AVAIABLE" ;
VAL_ 1195 APHMIInSVScrenResponse 153 "BLIND_SPOT_RIGHT" 152 "BLIND_SPOT_LEFT" 255 "NO_STREAM_CHANGE" 222 "DEBUG_RAW_CAMERAS_SFM" 221 "DEBUG_RAW_CAMERAS" 220 "DEBUG_COLOUR_BARS" 219 "DEBUG_CALIBRATION_OLMC_QUAD_VIEW" 218 "DEBUG_TESTSCREEN_4_CAMS" 217 "DEBUG_CALIBRATION_PGM_QUAD_VIEW" 216 "DEBUG_CALIBRATION_FLMC_QUAD_VIEW" 215 "DEBUG_RIGHT_CAMERA_CLEANING" 214 "DEBUG_RIGHT_CAMERA_EDGES" 213 "DEBUG_RIGHT_CAMERA_VECTORS" 212 "DEBUG_RIGHT_CAMERA_EXTERN" 211 "DEBUG_LEFT_CAMERA_CLEANING" 210 "DEBUG_LEFT_CAMERA_EDGES" 209 "DEBUG_LEFT_CAMERA_VECTORS" 208 "DEBUG_LEFT_CAMERA_EXTERN" 207 "DEBUG_REAR_CAMERA_CLEANING" 206 "DEBUG_REAR_CAMERA_EDGES" 205 "DEBUG_REAR_CAMERA_VECTORS" 204 "DEBUG_REAR_CAMERA_EXTERN" 203 "DEBUG_FRONT_CAMERA_CLEANING" 202 "DEBUG_FRONT_CAMERA_EDGES" 201 "DEBUG_FRONT_CAMERA_VECTORS" 200 "DEBUG_FRONT_CAMERA_EXTERN" 151 "SMARTPHONE_VIEW" 93 "IPA_TOP_VIEW" 92 "IPA_REAR_VIEW" 91 "IPA_FRONT_VIEW" 79 "ARA_PANORAMIC_IRREGULAR" 78 "ARA_PANORAMIC_NORMAL" 77 "ARA_REAR_IRREGULAR" 76 "ARA_REAR_NORMAL" 62 "KERB_VIEW_REAR" 61 "KERB_VIEW_FRONT" 49 "TRAILER_VIEW" 48 "PANORAMIC_REAR_VIEW" 47 "REAR_VIEW_SPLIT" 46 "REAR_VIEW_FULL" 34 "TOP_VIEW_PMD" 33 "TOP_VIEW_PSD" 32 "TOP_VIEW_SFM" 31 "TOP_VIEW" 18 "PANORAMIC_FRONT_VIEW" 17 "FRONT_VIEW_SPLIT" 16 "FRONT_VIEW_FULL" 15 "BOWL_VIEW_MODIFIED" 14 "BOWL_VIEW_14" 13 "BOWL_VIEW_13" 12 "BOWL_VIEW_12" 11 "BOWL_VIEW_11" 10 "BOWL_VIEW_10" 9 "BOWL_VIEW_9" 8 "BOWL_VIEW_8" 7 "BOWL_VIEW_7" 6 "BOWL_VIEW_6" 5 "BOWL_VIEW_5" 4 "BOWL_VIEW_4" 3 "BOWL_VIEW_3" 2 "BOWL_VIEW_2" 1 "BOWL_VIEW_1" 0 "BLANK_SCREEN" ;
VAL_ 1195 APHMIInStreamAvailable 0 "FALSE" 1 "TRUE" ;
VAL_ 1195 APHMIGeneralScreenRemote 19 "GP_MANEUVER_ACTIVE" 18 "GP_START" 17 "PDC_ACTIVE" 16 "KEY_CONTROL_ACTIVE" 0 "SYSTEM_NOT_ACTIVE" 1 "SCANNING_ACTIVE" 2 "PARKING_SPACE_SELECTION" 3 "REMOTE_APP_ACTIVE" 4 "MANEUVER_ACTIVE" 5 "MANEUVER_FINISHED" 6 "MANEUVER_INTERRUPTED" 7 "UNDO_MANEUVER_ACTIVE" 8 "START_REMOTE_APP" 9 "PARK_OUT_INIT" 10 "PARK_OUT_SIDE" 11 "MENU_REM" 12 "MANEUVER_ACTIVE_LONG_MAN" 13 "REM_SV" 14 "REM_MAN" 15 "REM_MAN_ACTIVE" ;
VAL_ 1195 APHMIGeneralMessageRemote 39 "PARKING_OUT_FINISHED_FALLBACK" 38 "PARKING_IN_FINISHED_FALLBACK" 37 "KEY_NOT_ALIVE" 36 "KEY_NOT_IN_RANGE" 35 "SLOW_DOWN" 34 "WAIT" 33 "LOW_ENERGY" 32 "UNDO_FINISHED" 31 "GARAGE_NOT_OPEN" 30 "PARKING_CANCELLED_STEER" 29 "PARKING_CANCELLED_THROTTLE" 28 "NO_REMOTE_DEVICE_CONNECTED" 27 "NO_REMOTE_DEVICE_PAIRED" 26 "SELECT_PARKING_VARIANT" 25 "SHIFT_TO_N" 24 "SHIFT_TO_P" 0 "NO_MESSAGE" 1 "VERY_CLOSE_TO_OBJECTS" 2 "START_PARKING_IN" 3 "PARKING_IN_FINISHED" 4 "PARKING_CANCELLED" 5 "PARKING_FAILED" 6 "SHIFT_TO_R" 7 "SHIFT_TO_D" 8 "SHIFT_TO_1" 9 "RELEASE_BRAKE" 10 "START_PARKING_OUT" 11 "PARKING_OUT_FINISHED" 12 "START_REM_MAN" 13 "REM_MAN_OBSTACLE_STOP" 14 "REDUCE_DISTANCE_TO_VEHICLE" 15 "CLOSE_DOOR_OR_START_REMOTE" 16 "RELEASE_HANDBRAKE" 17 "LEAVE_VEHICLE" 18 "NO_DRIVER_DETECTED_ON_SEAT" 19 "INTERNAL_SYSTEM_ERROR" 20 "PARKING_OUT_HANDOVER" 21 "STEERING_ACTIVE" 22 "STOP" 23 "MAX_WAITING_TIME_EXCEEDED" ;
VAL_ 380 Status_sensor_vert_acc 15 "Reserved" 14 "Reserved" 13 "Reserved" 12 "Reserved" 11 "Reserved" 10 "Reserved" 9 "Reserved" 8 "Reserved" 7 "Reserved" 6 "Reserved" 5 "Reserved" 4 "Initialization is running" 3 "Reserved" 2 "Signal failure" 1 "Sensor not available" 0 "No error" ;
VAL_ 380 Status_sensor_pitch_rate 15 "Reserved" 14 "Reserved" 13 "Reserved" 12 "Reserved" 11 "Reserved" 10 "Reserved" 9 "Reserved" 8 "Reserved" 7 "Reserved" 6 "Reserved" 5 "Reserved" 4 "Initialization is running" 3 "Reserved" 2 "Signal failure" 1 "Sensor not available" 0 "No error" ;
VAL_ 376 Status_sensor_roll_rate 15 "Reserved" 14 "Reserved" 13 "Reserved" 12 "Reserved" 11 "Reserved" 10 "Reserved" 9 "Reserved" 8 "Reserved" 7 "Reserved" 6 "Reserved" 5 "Reserved" 4 "Initialization is running" 3 "Reserved" 2 "Signal failure" 1 "Sensor not available" 0 "No error" ;
VAL_ 376 Status_sensor_long_acc 15 "Reserved" 14 "Reserved" 13 "Reserved" 12 "Reserved" 11 "Reserved" 10 "Reserved" 9 "Reserved" 8 "Reserved" 7 "Reserved" 6 "Reserved" 5 "Reserved" 4 "Initialization is running" 3 "Reserved" 2 "Signal failure" 1 "Sensor not available" 0 "No error" ;
VAL_ 372 Status_cluster 15 "Not defined" 14 "Not defined" 13 "Not defined" 12 "Not defined" 11 "Not defined" 10 "Not defined" 9 "Not defined" 8 "Synchronization failure" 7 "Not defined" 6 "Not defined" 5 "Not defined" 4 "Synchronization underflow" 3 "Not defined" 2 "Overvoltage detected" 1 "Undervoltage detected" 0 "No error" ;
VAL_ 372 Status_sensor_yaw_rate 15 "Reserved" 14 "Reserved" 13 "Reserved" 12 "Reserved" 11 "Reserved" 10 "Reserved" 9 "Reserved" 8 "Reserved" 7 "Reserved" 6 "Reserved" 5 "Reserved" 4 "Initialization is running" 3 "Reserved" 2 "Signal failure" 1 "Sensor not available" 0 "No error" ;
VAL_ 372 Status_sensor_lat_acc 15 "Reserved" 14 "Reserved" 13 "Reserved" 12 "Reserved" 11 "Reserved" 10 "Reserved" 9 "Reserved" 8 "Reserved" 7 "Reserved" 6 "Reserved" 5 "Reserved" 4 "Initialization is running" 3 "Reserved" 2 "Signal failure" 1 "Sensor not available" 0 "No error" ;
VAL_ 1189 APHMIOutUserSVScreenRequest 226 "DEBUG_IMAGE_HARMONIZATION" 225 "DEBUG_PGM_QUAD_OVERLAY" 224 "DEBUG_HEIGHT_MAP" 223 "DEBUG_CURB_MESH_DEMO" 182 "RAW_CAMERAS_SFM" 181 "RAW_CAMERAS" 176 "STATIC_SPLIT_BOWL" 175 "ADAPTIVE_SPLIT_BOWL" 174 "STATIC_BOWL" 173 "ADAPTIVE_FULL_BOWL" 168 "TRANSPARENT_GHOST" 167 "TRANSPARENT_ALPHA" 166 "TRANSPARENT_HOOD" 123 "MORPH_ARA" 122 "MORPH_REAR_FULL" 121 "MORPH_REAR" 107 "MORPH_FRONT_FULL" 106 "MORPH_FRONT" 99 "PARK_TRANSPARENT_PDW" 98 "PARK_WARN_TOP_VIEW" 97 "PARK_SPACES_TOP_VIEW" 96 "PARK_TOP_VIEW" 95 "PARK_REAR_VIEW" 94 "PARK_FRONT_VIEW" 255 "NO_STREAM_CHANGE" 222 "DEBUG_RAW_CAMERAS_SFM" 221 "DEBUG_RAW_CAMERAS" 220 "DEBUG_COLOUR_BARS" 219 "DEBUG_CALIBRATION_OLMC_QUAD_VIEW" 218 "DEBUG_TESTSCREEN_4_CAMS" 217 "DEBUG_CALIBRATION_PGM_QUAD_VIEW" 216 "DEBUG_CALIBRATION_FLMC_QUAD_VIEW" 215 "DEBUG_RIGHT_CAMERA_CLEANING" 214 "DEBUG_RIGHT_CAMERA_EDGES" 213 "DEBUG_RIGHT_CAMERA_VECTORS" 212 "DEBUG_RIGHT_CAMERA_EXTERN" 211 "DEBUG_LEFT_CAMERA_CLEANING" 210 "DEBUG_LEFT_CAMERA_EDGES" 209 "DEBUG_LEFT_CAMERA_VECTORS" 208 "DEBUG_LEFT_CAMERA_EXTERN" 207 "DEBUG_REAR_CAMERA_CLEANING" 206 "DEBUG_REAR_CAMERA_EDGES" 205 "DEBUG_REAR_CAMERA_VECTORS" 204 "DEBUG_REAR_CAMERA_EXTERN" 203 "DEBUG_FRONT_CAMERA_CLEANING" 202 "DEBUG_FRONT_CAMERA_EDGES" 201 "DEBUG_FRONT_CAMERA_VECTORS" 200 "DEBUG_FRONT_CAMERA_EXTERN" 151 "SMARTPHONE_VIEW" 93 "IPA_TOP_VIEW" 92 "IPA_REAR_VIEW" 91 "IPA_FRONT_VIEW" 79 "ARA_PANORAMIC_IRREGULAR" 78 "ARA_PANORAMIC_NORMAL" 77 "ARA_REAR_IRREGULAR" 76 "ARA_REAR_NORMAL" 62 "KERB_VIEW_REAR" 61 "KERB_VIEW_FRONT" 49 "TRAILER_VIEW" 48 "PANORAMIC_REAR_VIEW" 47 "REAR_VIEW_SPLIT" 46 "REAR_VIEW_FULL" 34 "TOP_VIEW_PMD" 33 "TOP_VIEW_PSD" 32 "TOP_VIEW_SFM" 31 "TOP_VIEW" 18 "PANORAMIC_FRONT_VIEW" 17 "FRONT_VIEW_SPLIT" 16 "FRONT_VIEW_FULL" 15 "BOWL_VIEW_MODIFIED" 14 "BOWL_VIEW_14" 13 "BOWL_VIEW_13" 12 "BOWL_VIEW_12" 11 "BOWL_VIEW_11" 10 "BOWL_VIEW_10" 9 "BOWL_VIEW_9" 8 "BOWL_VIEW_8" 7 "BOWL_VIEW_7" 6 "BOWL_VIEW_6" 5 "BOWL_VIEW_5" 4 "BOWL_VIEW_4" 3 "BOWL_VIEW_3" 2 "BOWL_VIEW_2" 1 "BOWL_VIEW_1" 0 "BLANK_SCREEN" ;
VAL_ 1189 APHMIOutUserActionRem 30 "TAP_ON_PREVIOUS_SCREEN" 29 "TAP_ON_REM_BWD" 28 "TAP_ON_REM_FWD" 27 "TAP_ON_REM_SV" 26 "TAP_ON_REM_MAN" 25 "TAP_ON_PARK_OUT" 24 "TAP_ON_PARK_IN" 23 "TAP_ON_REDO" 22 "TAP_ON_CANCEL" 21 "TAP_ON_UNDO" 20 "TAP_ON_CONTINUE" 19 "TAP_ON_INTERRUPT" 18 "TAP_ON_START_PARKING" 17 "APP_CLOSED" 16 "APP_STARTED" 4 "TAP_ON_PARKING_SPACE_4" 3 "TAP_ON_PARKING_SPACE_3" 2 "TAP_ON_PARKING_SPACE_2" 1 "TAP_ON_PARKING_SPACE_1" 0 "NO_USER_ACTION" ;
VAL_ 1189 APHMIOutScreenRem 16 "KEY_CONTROL_ACTIVE" 0 "SYSTEM_NOT_ACTIVE" 1 "SCANNING_ACTIVE" 2 "PARKING_SPACE_SELECTION" 3 "REMOTE_APP_ACTIVE" 4 "MANEUVER_ACTIVE" 5 "MANEUVER_FINISHED" 6 "MANEUVER_INTERRUPTED" 7 "UNDO_MANEUVER_ACTIVE" 8 "START_REMOTE_APP" 9 "PARK_OUT_INIT" 10 "PARK_OUT_SIDE" 11 "MENU_REM" 12 "MANEUVER_ACTIVE_LONG_MAN" 13 "REM_SV" 14 "REM_MAN" 15 "REM_MAN_ACTIVE" ;
VAL_ 1189 APHMIOutScreenHU 0 "SYSTEM_NOT_ACTIVE" 1 "SCANNING_ACTIVE" 2 "PARKING_SPACE_SELECTION" 3 "REMOTE_APP_ACTIVE" 4 "MANEUVER_ACTIVE" 5 "MANEUVER_FINISHED" 6 "MANEUVER_INTERRUPTED" 7 "UNDO_MANEUVER_ACTIVE" 8 "START_REMOTE_APP" 9 "PARK_OUT_INIT" 10 "PARK_OUT_SIDE" 11 "MENU_REM" 12 "MANEUVER_ACTIVE_LONG_MAN" 13 "REM_SV" 14 "REM_MAN" 15 "REM_MAN_ACTIVE" ;
VAL_ 1189 APHMIOutUserActionHU 62 "TAP_ON_USER_SLOT_CLOSE" 61 "TAP_ON_USER_SLOT_REFINE" 60 "TAP_ON_MEMORY_SLOT_3" 59 "TAP_ON_MEMORY_SLOT_2" 58 "TAP_ON_MEMORY_SLOT_1" 57 "TAP_ON_MEMORY_PARKING" 56 "TAP_ON_MUTE" 55 "TAP_ON_REVERSE_ASSIST" 54 "TAP_ON_EXPLICIT_SCANNING" 53 "TAP_ON_USER_SLOT_SAVE" 52 "TAP_ON_USER_SLOT_RESET" 51 "TAP_ON_USER_SLOT_ROT_CTRCLKWISE" 50 "TAP_ON_USER_SLOT_ROT_CLKWISE" 49 "TAP_ON_USER_SLOT_MOVE_RIGHT" 48 "TAP_ON_USER_SLOT_MOVE_LEFT" 47 "TAP_ON_USER_SLOT_MOVE_DOWN" 46 "TAP_ON_USER_SLOT_MOVE_UP" 45 "TAP_ON_USER_SLOT_RIGHT_PERP_FWD" 44 "TAP_ON_USER_SLOT_RIGHT_PERP_BWD" 43 "TAP_ON_USER_SLOT_RIGHT_PAR" 42 "TAP_ON_USER_SLOT_LEFT_PERP_FWD" 41 "TAP_ON_USER_SLOT_LEFT_PERP_BWD" 40 "TAP_ON_USER_SLOT_LEFT_PAR" 39 "TAP_ON_WHP" 38 "TAP_ON_SWITCH_TO_REMOTE_APP" 37 "TAP_ON_SWITCH_TO_REMOTE_KEY" 36 "TAP_ON_AP_PDC_TOGGLE_VIEW" 35 "TAP_ON_PDC" 34 "TAP_ON_RM" 33 "TAP_ON_GP" 32 "TAP_ON_START_REM_PARK_KEY" 31 "TAP_ON_SEMI_AUTOMATED_PARKING" 30 "TAP_ON_FULLY_AUTOMATED_PARKING" 29 "TAP_ON_LSCA_RELEASE_BRAKE" 0 "NO_USER_ACTION" 1 "TAP_ON_PARKING_SPACE_LEFT_1" 2 "TAP_ON_PARKING_SPACE_LEFT_2" 3 "TAP_ON_PARKING_SPACE_LEFT_3" 4 "TAP_ON_PARKING_SPACE_LEFT_4" 5 "TAP_ON_PARKING_SPACE_RIGHT_1" 6 "TAP_ON_PARKING_SPACE_RIGHT_2" 7 "TAP_ON_PARKING_SPACE_RIGHT_3" 8 "TAP_ON_PARKING_SPACE_RIGHT_4" 9 "TAP_ON_PARKING_SPACE_FRONT_1" 10 "TAP_ON_PARKING_SPACE_FRONT_2" 11 "TAP_ON_PARKING_SPACE_FRONT_3" 12 "TAP_ON_PARKING_SPACE_FRONT_4" 13 "TAP_ON_PARKING_SPACE_REAR_1" 14 "TAP_ON_PARKING_SPACE_REAR_2" 15 "TAP_ON_PARKING_SPACE_REAR_3" 16 "TAP_ON_PARKING_SPACE_REAR_4" 17 "TAP_ON_START_SELECTION" 18 "TAP_ON_START_PARKING" 19 "TAP_ON_INTERRUPT" 20 "TAP_ON_CONTINUE" 21 "TAP_ON_UNDO" 22 "TAP_ON_CANCEL" 23 "TAP_ON_REDO" 24 "TAP_ON_START_REM_PARK_PHONE" 25 "TAP_ON_SWITCH_DIRECTION" 26 "TAP_ON_SWITCH_ORIENTATION" 27 "TAP_ON_PREVIOUS_SCREEN" 28 "TOGGLE_AP_ACTIVE" ;
VAL_ 1194 ParkDistViewHigh40 0 "H_NOT_OCCUPIED" 1 "H_OUTERMOST_BAR_OCCUPIED" 2 "H_BAR_2_OCCUPIED" 3 "H_BAR_3_OCCUPIED" 4 "H_BAR_4_OCCUPIED" 5 "H_BAR_5_OCCUPIED" 6 "H_BAR_6_OCCUPIED" 7 "H_INNERMOST_BAR_OCCUPIED" ;
VAL_ 1194 ParkDistViewHigh39 0 "H_NOT_OCCUPIED" 1 "H_OUTERMOST_BAR_OCCUPIED" 2 "H_BAR_2_OCCUPIED" 3 "H_BAR_3_OCCUPIED" 4 "H_BAR_4_OCCUPIED" 5 "H_BAR_5_OCCUPIED" 6 "H_BAR_6_OCCUPIED" 7 "H_INNERMOST_BAR_OCCUPIED" ;
VAL_ 1194 ParkDistViewHigh38 0 "H_NOT_OCCUPIED" 1 "H_OUTERMOST_BAR_OCCUPIED" 2 "H_BAR_2_OCCUPIED" 3 "H_BAR_3_OCCUPIED" 4 "H_BAR_4_OCCUPIED" 5 "H_BAR_5_OCCUPIED" 6 "H_BAR_6_OCCUPIED" 7 "H_INNERMOST_BAR_OCCUPIED" ;
VAL_ 1194 ParkDistViewHigh37 0 "H_NOT_OCCUPIED" 1 "H_OUTERMOST_BAR_OCCUPIED" 2 "H_BAR_2_OCCUPIED" 3 "H_BAR_3_OCCUPIED" 4 "H_BAR_4_OCCUPIED" 5 "H_BAR_5_OCCUPIED" 6 "H_BAR_6_OCCUPIED" 7 "H_INNERMOST_BAR_OCCUPIED" ;
VAL_ 1194 ParkDistViewHigh36 0 "H_NOT_OCCUPIED" 1 "H_OUTERMOST_BAR_OCCUPIED" 2 "H_BAR_2_OCCUPIED" 3 "H_BAR_3_OCCUPIED" 4 "H_BAR_4_OCCUPIED" 5 "H_BAR_5_OCCUPIED" 6 "H_BAR_6_OCCUPIED" 7 "H_INNERMOST_BAR_OCCUPIED" ;
VAL_ 1194 ParkDistViewHigh35 0 "H_NOT_OCCUPIED" 1 "H_OUTERMOST_BAR_OCCUPIED" 2 "H_BAR_2_OCCUPIED" 3 "H_BAR_3_OCCUPIED" 4 "H_BAR_4_OCCUPIED" 5 "H_BAR_5_OCCUPIED" 6 "H_BAR_6_OCCUPIED" 7 "H_INNERMOST_BAR_OCCUPIED" ;
VAL_ 1194 ParkDistViewHigh34 0 "H_NOT_OCCUPIED" 1 "H_OUTERMOST_BAR_OCCUPIED" 2 "H_BAR_2_OCCUPIED" 3 "H_BAR_3_OCCUPIED" 4 "H_BAR_4_OCCUPIED" 5 "H_BAR_5_OCCUPIED" 6 "H_BAR_6_OCCUPIED" 7 "H_INNERMOST_BAR_OCCUPIED" ;
VAL_ 1194 ParkDistViewHigh33 0 "H_NOT_OCCUPIED" 1 "H_OUTERMOST_BAR_OCCUPIED" 2 "H_BAR_2_OCCUPIED" 3 "H_BAR_3_OCCUPIED" 4 "H_BAR_4_OCCUPIED" 5 "H_BAR_5_OCCUPIED" 6 "H_BAR_6_OCCUPIED" 7 "H_INNERMOST_BAR_OCCUPIED" ;
VAL_ 1194 ParkDistViewHigh32 0 "H_NOT_OCCUPIED" 1 "H_OUTERMOST_BAR_OCCUPIED" 2 "H_BAR_2_OCCUPIED" 3 "H_BAR_3_OCCUPIED" 4 "H_BAR_4_OCCUPIED" 5 "H_BAR_5_OCCUPIED" 6 "H_BAR_6_OCCUPIED" 7 "H_INNERMOST_BAR_OCCUPIED" ;
VAL_ 1194 ParkDistViewHigh31 0 "H_NOT_OCCUPIED" 1 "H_OUTERMOST_BAR_OCCUPIED" 2 "H_BAR_2_OCCUPIED" 3 "H_BAR_3_OCCUPIED" 4 "H_BAR_4_OCCUPIED" 5 "H_BAR_5_OCCUPIED" 6 "H_BAR_6_OCCUPIED" 7 "H_INNERMOST_BAR_OCCUPIED" ;
VAL_ 1193 PDCRear1IntersectDrvTube 0 "FALSE" 1 "TRUE" ;
VAL_ 1193 PDCRear2IntersectDrvTube 0 "FALSE" 1 "TRUE" ;
VAL_ 1193 PDCRear3IntersectDrvTube 0 "FALSE" 1 "TRUE" ;
VAL_ 1193 PDCRear4IntersectDrvTube 0 "FALSE" 1 "TRUE" ;
VAL_ 1193 PDCRight1IntersectDrvTube 0 "FALSE" 1 "TRUE" ;
VAL_ 1193 PDCRight2IntersectDrvTube 0 "FALSE" 1 "TRUE" ;
VAL_ 1193 PDCRight3IntersectDrvTube 0 "FALSE" 1 "TRUE" ;
VAL_ 1193 PDCRight4IntersectDrvTube 0 "FALSE" 1 "TRUE" ;
VAL_ 1192 PDCFront1IntersectDrvTube 0 "FALSE" 1 "TRUE" ;
VAL_ 1192 PDCFront2IntersectDrvTube 0 "FALSE" 1 "TRUE" ;
VAL_ 1192 PDCFront3IntersectDrvTube 0 "FALSE" 1 "TRUE" ;
VAL_ 1192 PDCFront4IntersectDrvTube 0 "FALSE" 1 "TRUE" ;
VAL_ 1192 PDCLeft1IntersectDrvTube 0 "FALSE" 1 "TRUE" ;
VAL_ 1192 PDCLeft2IntersectDrvTube 0 "FALSE" 1 "TRUE" ;
VAL_ 1192 PDCLeft3IntersectDrvTube 0 "FALSE" 1 "TRUE" ;
VAL_ 1192 PDCLeft4IntersectDrvTube 0 "FALSE" 1 "TRUE" ;
VAL_ 1191 DrivingTubeDirection 1 "LEFT" 0 "RIGHT" ;
VAL_ 1191 DrivingTubeDisplay 3 "BOTH" 2 "REAR" 1 "FRONT" 0 "NONE" ;
VAL_ 1191 DrivingTubeRearRadius 65535 "UNKNOWN" 65534 "INFINITE" ;
VAL_ 1191 DrivingTubeFrontRadius 65535 "UNKNOWN" 65534 "INFINITE" ;
VAL_ 1191 PDCShutdownCause 3 "SHUTDOWN_BY_SPEED" 2 "SHUTDOWN_BY_DISENGAGED_R_GEAR" 1 "SHUTDOWN_BY_BUTTON" 0 "NON_SYS_ACTIVE" ;
VAL_ 1191 PDCSystemState 5 "FAILURE" 4 "AUTOMATICALLY_ACTIVATED" 3 "ACTIVATED_BY_BUTTON" 2 "ACTIVATED_BY_R_GEAR" 1 "OFF" 0 "INIT" ;
VAL_ 1190 USSDistanceFrontCenterLeft 0 "L_NOT_OCCUPIED" 1 "L_OUTERMOST_BAR_OCCUPIED" 2 "L_BAR_2_OCCUPIED" 3 "L_INNERMOST_BAR_OCCUPIED" ;
VAL_ 1190 USSDistanceFrontLeft 0 "L_NOT_OCCUPIED" 1 "L_OUTERMOST_BAR_OCCUPIED" 2 "L_BAR_2_OCCUPIED" 3 "L_INNERMOST_BAR_OCCUPIED" ;
VAL_ 1190 USSDistanceSideFrontLeft 0 "L_NOT_OCCUPIED" 1 "L_OUTERMOST_BAR_OCCUPIED" 2 "L_BAR_2_OCCUPIED" 3 "L_INNERMOST_BAR_OCCUPIED" ;
VAL_ 1190 USSDistanceSideRearLeft 0 "L_NOT_OCCUPIED" 1 "L_OUTERMOST_BAR_OCCUPIED" 2 "L_BAR_2_OCCUPIED" 3 "L_INNERMOST_BAR_OCCUPIED" ;
VAL_ 1190 USSDistanceRearLeft 0 "L_NOT_OCCUPIED" 1 "L_OUTERMOST_BAR_OCCUPIED" 2 "L_BAR_2_OCCUPIED" 3 "L_INNERMOST_BAR_OCCUPIED" ;
VAL_ 1190 USSDistanceRearCenterLeft 0 "L_NOT_OCCUPIED" 1 "L_OUTERMOST_BAR_OCCUPIED" 2 "L_BAR_2_OCCUPIED" 3 "L_INNERMOST_BAR_OCCUPIED" ;
VAL_ 1190 USSDistanceRearCenterRight 0 "L_NOT_OCCUPIED" 1 "L_OUTERMOST_BAR_OCCUPIED" 2 "L_BAR_2_OCCUPIED" 3 "L_INNERMOST_BAR_OCCUPIED" ;
VAL_ 1190 USSDistanceRearRight 0 "L_NOT_OCCUPIED" 1 "L_OUTERMOST_BAR_OCCUPIED" 2 "L_BAR_2_OCCUPIED" 3 "L_INNERMOST_BAR_OCCUPIED" ;
VAL_ 1190 USSDistanceSideRearRight 0 "L_NOT_OCCUPIED" 1 "L_OUTERMOST_BAR_OCCUPIED" 2 "L_BAR_2_OCCUPIED" 3 "L_INNERMOST_BAR_OCCUPIED" ;
VAL_ 1190 USSDistanceSideFrontRight 0 "L_NOT_OCCUPIED" 1 "L_OUTERMOST_BAR_OCCUPIED" 2 "L_BAR_2_OCCUPIED" 3 "L_INNERMOST_BAR_OCCUPIED" ;
VAL_ 1190 USSDistanceFrontRight 0 "L_NOT_OCCUPIED" 1 "L_OUTERMOST_BAR_OCCUPIED" 2 "L_BAR_2_OCCUPIED" 3 "L_INNERMOST_BAR_OCCUPIED" ;
VAL_ 1190 USSDistanceFrontCenterRight 0 "L_NOT_OCCUPIED" 1 "L_OUTERMOST_BAR_OCCUPIED" 2 "L_BAR_2_OCCUPIED" 3 "L_INNERMOST_BAR_OCCUPIED" ;
VAL_ 1188 ParkSituationRear 10 "ANGLED_REV" 9 "ANGLED_OUT" 8 "PERPENDICULAR_OUT" 0 "NO_SITUATION" 1 "PERPENDICULAR" 2 "PARALLEL" 3 "ANGLED" 4 "STREET" 5 "UNCERTAIN" 6 "PARALLEL_OUT" 7 "NOT_AVAILABLE" 15 "SNA" ;
VAL_ 1187 ParkSituationFront 10 "ANGLED_REV" 9 "ANGLED_OUT" 8 "PERPENDICULAR_OUT" 0 "NO_SITUATION" 1 "PERPENDICULAR" 2 "PARALLEL" 3 "ANGLED" 4 "STREET" 5 "UNCERTAIN" 6 "PARALLEL_OUT" 7 "NOT_AVAILABLE" 15 "SNA" ;
VAL_ 1186 ParkSituationRight 10 "ANGLED_REV" 9 "ANGLED_OUT" 8 "PERPENDICULAR_OUT" 0 "NO_SITUATION" 1 "PERPENDICULAR" 2 "PARALLEL" 3 "ANGLED" 4 "STREET" 5 "UNCERTAIN" 6 "PARALLEL_OUT" 7 "NOT_AVAILABLE" 15 "SNA" ;
VAL_ 1185 ParkSituationLeft 10 "ANGLED_REV" 9 "ANGLED_OUT" 8 "PERPENDICULAR_OUT" 0 "NO_SITUATION" 1 "PERPENDICULAR" 2 "PARALLEL" 3 "ANGLED" 4 "STREET" 5 "UNCERTAIN" 6 "PARALLEL_OUT" 7 "NOT_AVAILABLE" 15 "SNA" ;
VAL_ 1184 APHMIGeneralRevAssistPoss 1 "TRUE" 0 "FALSE" ;
VAL_ 1184 APHMIGeneralParkInOutFinished 0 "FALSE" 1 "TRUE" ;
VAL_ 1184 APHMIGeneralRemKeyPoss 0 "FALSE" 1 "TRUE" ;
VAL_ 1184 APHMIGeneralMaxSpeed10Warning 2 "BLINKING" 1 "CONTINUOUS" 0 "OFF" ;
VAL_ 1184 APHMIGeneralSemiAutomParkPoss 0 "FALSE" 1 "TRUE" ;
VAL_ 1184 APHMIGeneralFullyAutomParkPoss 0 "FALSE" 1 "TRUE" ;
VAL_ 1184 APHMIGeneralCurrentGear 0 "GEAR_N" 1 "GEAR_01" 2 "GEAR_02" 3 "GEAR_03" 4 "GEAR_04" 5 "GEAR_05" 6 "GEAR_06" 7 "GEAR_07" 8 "GEAR_08" 9 "GEAR_P" 10 "GEAR_S" 11 "GEAR_D" 12 "GEAR_INTERMEDIATE_POS" 13 "GEAR_R" 14 "GEAR_NOT_DEFINED" 15 "GEAR_ERROR" ;
VAL_ 1184 APHMIParkingProcedureCtrlState 0 "PPC_INACTIVE" 1 "PPC_BEHAVIOR_INACTIVE" 2 "PPC_SCANNING_INACTIVE" 3 "PPC_SCANNING_IN" 4 "PPC_SCANNING_OUT" 5 "PPC_SCANNING_RM" 6 "PPC_PARKING_INACTIVE" 7 "PPC_PREPARE_PARKING" 8 "PPC_PERFORM_PARKING" 9 "PPC_PARKING_PAUSE" 10 "PPC_PARKING_FAILED" 11 "PPC_OFFER_HANDOVER" 12 "PPC_SUCCESS" 13 "PPC_PARKING_CANCELED" 14 "PPC_IRREVERSIBLE_ERROR" 15 "PPC_REVERSIBLE_ERROR" 23 "PPC_DEMO_OFF" ;
VAL_ 1184 APHMIGeneralAVGType 15 "GP_GENERAL" 0 "NO_AVG_TYPE" 1 "PARK_IN_PARALLEL_LEFT" 2 "PARK_IN_PARALLEL_RIGHT" 3 "PARK_IN_PERPENDICULAR_LEFT_FWD" 4 "PARK_IN_PERPENDICULAR_LEFT_BWD" 5 "PARK_IN_PERPENDICULAR_RIGHT_FWD" 6 "PARK_IN_PERPENDICULAR_RIGHT_BWD" 7 "PARK_OUT_PARALLEL_LEFT" 8 "PARK_OUT_PARALLEL_RIGHT" 9 "PARK_OUT_PERPENDICULAR_LEFT_FWD" 10 "PARK_OUT_PERPENDICULAR_LEFT_BWD" 11 "PARK_OUT_PERPENDICULAR_RIGHT_FWD" 12 "PARK_OUT_PERPENDICULAR_RIGHT_BWD" 13 "REM_MAN_FWD" 14 "REM_MAN_BWD" ;
VAL_ 1184 APHMIGeneralDrivingDir 0 "NO_DIRECTION" 1 "FORWARDS" 2 "BACKWARDS" ;
VAL_ 1184 APHMIGeneralBtnForwardPoss 0 "FALSE" 1 "TRUE" ;
VAL_ 1184 APHMIGeneralBtnBackwardPoss 0 "FALSE" 1 "TRUE" ;
VAL_ 1184 APHMIGeneralSVPoss 0 "FALSE" 1 "TRUE" ;
VAL_ 1184 APHMIGeneralUndoPoss 0 "FALSE" 1 "TRUE" ;
VAL_ 1184 APHMIGeneralRemManPoss 0 "FALSE" 1 "TRUE" ;
VAL_ 1184 APHMIGeneralParkOutPoss 0 "FALSE" 1 "TRUE" ;
VAL_ 1184 APHMIGeneralParkInPoss 0 "FALSE" 1 "TRUE" ;
VAL_ 1184 APHMIGeneralContinuePoss 0 "FALSE" 1 "TRUE" ;
VAL_ 1184 APHMIGeneralRemCtrlPoss 0 "FALSE" 1 "TRUE" ;
VAL_ 1184 APHMIGeneralRemCtrlSelected 0 "FALSE" 1 "TRUE" ;
VAL_ 1184 APHMIGeneralRemAppActive 0 "FALSE" 1 "TRUE" ;
VAL_ 1184 APHMIGeneralMessage 57 "MEMORY_PARKING_FAILED" 56 "MEMORY_PARKING_CANCELLED" 55 "MEMORY_PARKING_FINISHED" 54 " DIAG_USS_12_NOT_RUNNING" 53 " DIAG_USS_11_NOT_RUNNING" 52 " DIAG_USS_10_NOT_RUNNING" 51 " DIAG_USS_9_NOT_RUNNING" 50 " DIAG_USS_8_NOT_RUNNING" 49 " DIAG_USS_7_NOT_RUNNING" 48 " DIAG_USS_6_NOT_RUNNING" 47 " DIAG_USS_5_NOT_RUNNING" 46 " DIAG_USS_4_NOT_RUNNING" 45 " DIAG_USS_3_NOT_RUNNING" 44 " DIAG_USS_2_NOT_RUNNING" 43 " DIAG_USS_1_NOT_RUNNING" 42 "REVERSE_ASSIST_FAILED" 41 "REVERSE_ASSIST_CANCELLED" 40 "REVERSE_ASSIST_FINISHED" 39 "PARKING_OUT_FINISHED_FALLBACK" 38 "PARKING_IN_FINISHED_FALLBACK" 37 "KEY_NOT_ALIVE" 36 "KEY_NOT_IN_RANGE" 35 "SLOW_DOWN" 34 "WAIT" 33 "LOW_ENERGY" 32 "UNDO_FINISHED" 31 "GARAGE_NOT_OPEN" 30 "PARKING_CANCELLED_STEER" 29 "PARKING_CANCELLED_THROTTLE" 28 "NO_REMOTE_DEVICE_CONNECTED" 27 "NO_REMOTE_DEVICE_PAIRED" 26 "SELECT_PARKING_VARIANT" 25 "SHIFT_TO_N" 24 "SHIFT_TO_P" 0 "NO_MESSAGE" 1 "VERY_CLOSE_TO_OBJECTS" 2 "START_PARKING_IN" 3 "PARKING_IN_FINISHED" 4 "PARKING_CANCELLED" 5 "PARKING_FAILED" 6 "SHIFT_TO_R" 7 "SHIFT_TO_D" 8 "SHIFT_TO_1" 9 "RELEASE_BRAKE" 10 "START_PARKING_OUT" 11 "PARKING_OUT_FINISHED" 12 "START_REM_MAN" 13 "REM_MAN_OBSTACLE_STOP" 14 "REDUCE_DISTANCE_TO_VEHICLE" 15 "CLOSE_DOOR_OR_START_REMOTE" 16 "RELEASE_HANDBRAKE" 17 "LEAVE_VEHICLE" 18 "NO_DRIVER_DETECTED_ON_SEAT" 19 "INTERNAL_SYSTEM_ERROR" 20 "PARKING_OUT_HANDOVER" 21 "STEERING_ACTIVE" 22 "STOP" 23 "MAX_WAITING_TIME_EXCEEDED" ;
VAL_ 1184 APHMIGeneralScreen 20 "DIAG_ERROR" 19 "GP_MANEUVER_ACTIVE" 18 "GP_START" 17 "PDC_ACTIVE" 16 "KEY_CONTROL_ACTIVE" 0 "SYSTEM_NOT_ACTIVE" 1 "SCANNING_ACTIVE" 2 "PARKING_SPACE_SELECTION" 3 "REMOTE_APP_ACTIVE" 4 "MANEUVER_ACTIVE" 5 "MANEUVER_FINISHED" 6 "MANEUVER_INTERRUPTED" 7 "UNDO_MANEUVER_ACTIVE" 8 "START_REMOTE_APP" 9 "PARK_OUT_INIT" 10 "PARK_OUT_SIDE" 11 "MENU_REM" 12 "MANEUVER_ACTIVE_LONG_MAN" 13 "REM_SV" 14 "REM_MAN" 15 "REM_MAN_ACTIVE" ;
